VERSION ""

NS_ :

BS_:

BU_: Main_Module Torque_Vector_fpga Driveline a_box OrionBMS torque_vector Dashboard Steering PDU Acceleration bootloader BMS_LV BITSTREAM Charger DAQ a_box ARDUINO TEST_NODE TEST_NODE_2 DAQ

BO_ 2214598913 main_hb: 2 Main_Module
 SG_ precharge_state : 8|1@1+ (1,0) [0|0] "" Vector__XXX
 SG_ car_state : 0|8@1+ (1,0) [0|0] "" Vector__XXX

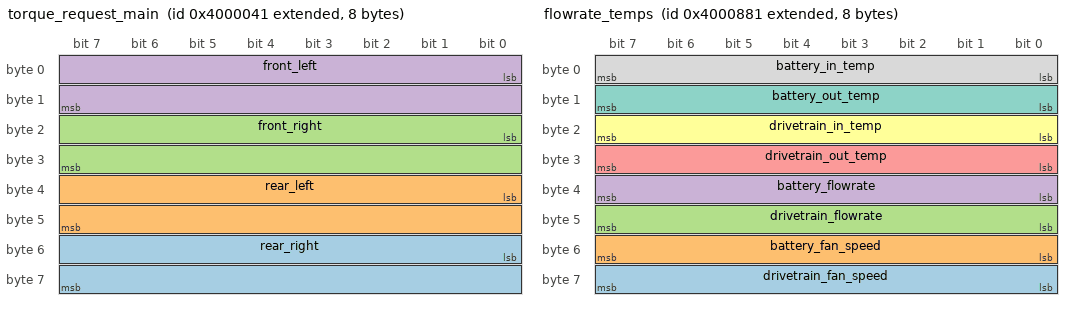
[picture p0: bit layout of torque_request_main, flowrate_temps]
BO_ 2214592577 torque_request_main: 8 Main_Module
 SG_ rear_right : 48|16@1- (1,0) [0|0] "" Vector__XXX
 SG_ rear_left : 32|16@1- (1,0) [0|0] "" Vector__XXX
 SG_ front_right : 16|16@1- (1,0) [0|0] "" Vector__XXX
 SG_ front_left : 0|16@1- (1,0) [0|0] "" Vector__XXX

BO_ 2214594689 flowrate_temps: 8 Main_Module
 SG_ drivetrain_fan_speed : 56|8@1+ (100,0) [0|0] "RPM" Vector__XXX
 SG_ battery_fan_speed : 48|8@1+ (100,0) [0|0] "RPM" Vector__XXX
 SG_ drivetrain_flowrate : 40|8@1+ (0.1,0) [0|0] "LPM" Vector__XXX
 SG_ battery_flowrate : 32|8@1+ (0.1,0) [0|0] "LPM" Vector__XXX
 SG_ drivetrain_out_temp : 24|8@1- (1,0) [0|0] "C" Vector__XXX
 SG_ drivetrain_in_temp : 16|8@1- (1,0) [0|0] "C" Vector__XXX
 SG_ battery_out_temp : 8|8@1- (1,0) [0|0] "C" Vector__XXX
 SG_ battery_in_temp : 0|8@1- (1,0) [0|0] "C" Vector__XXX

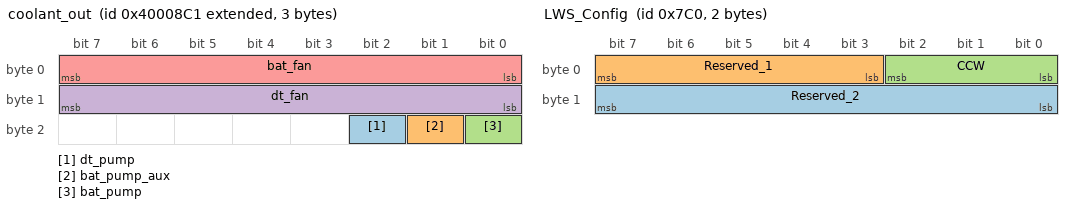
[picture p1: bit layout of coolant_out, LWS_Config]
BO_ 2214594753 coolant_out: 3 Main_Module
 SG_ dt_pump : 18|1@1+ (1,0) [0|0] "" Vector__XXX
 SG_ bat_pump_aux : 17|1@1+ (1,0) [0|0] "" Vector__XXX
 SG_ bat_pump : 16|1@1+ (1,0) [0|0] "" Vector__XXX
 SG_ dt_fan : 8|8@1+ (1,0) [0|0] "%" Vector__XXX
 SG_ bat_fan : 0|8@1+ (1,0) [0|0] "%" Vector__XXX

BO_ 2415921409 gearbox: 2 Main_Module
 SG_ r_temp : 8|8@1- (1,0) [0|0] "" Vector__XXX
 SG_ l_temp : 0|8@1- (1,0) [0|0] "" Vector__XXX

BO_ 1984 LWS_Config: 2 Main_Module
 SG_ Reserved_2 : 8|8@1+ (1,0) [0|0] "" Vector__XXX
 SG_ Reserved_1 : 3|5@1+ (1,0) [0|0] "" Vector__XXX
 SG_ CCW : 0|3@1+ (1,0) [0|0] "" Vector__XXX

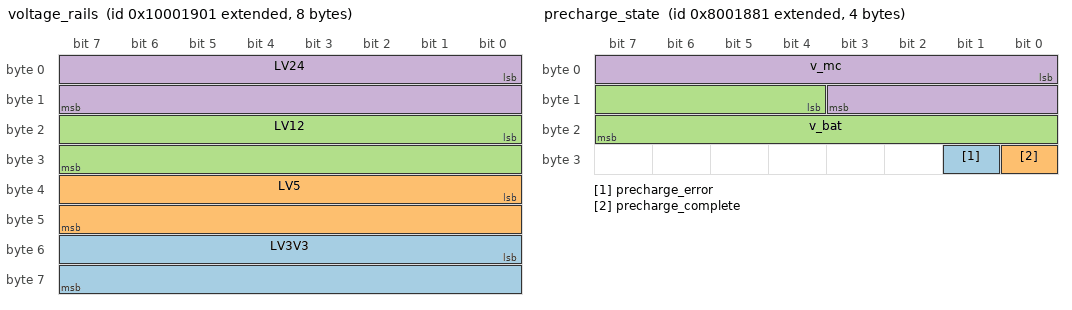
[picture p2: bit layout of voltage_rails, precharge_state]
BO_ 2415925505 voltage_rails: 8 Main_Module
 SG_ LV3V3 : 48|16@1+ (1,0) [0|0] "mV" Vector__XXX
 SG_ LV5 : 32|16@1+ (1,0) [0|0] "mV" Vector__XXX
 SG_ LV12 : 16|16@1+ (1,0) [0|0] "mV" Vector__XXX
 SG_ LV24 : 0|16@1+ (1,0) [0|0] "mV" Vector__XXX

BO_ 2281707649 precharge_state: 4 Main_Module
 SG_ precharge_error : 25|1@1+ (1,0) [0|0] "" Vector__XXX
 SG_ precharge_complete : 24|1@1+ (1,0) [0|0] "" Vector__XXX
 SG_ v_bat : 12|12@1+ (0.1,0) [0|0] "V" Vector__XXX
 SG_ v_mc : 0|12@1+ (0.1,0) [0|0] "V" Vector__XXX

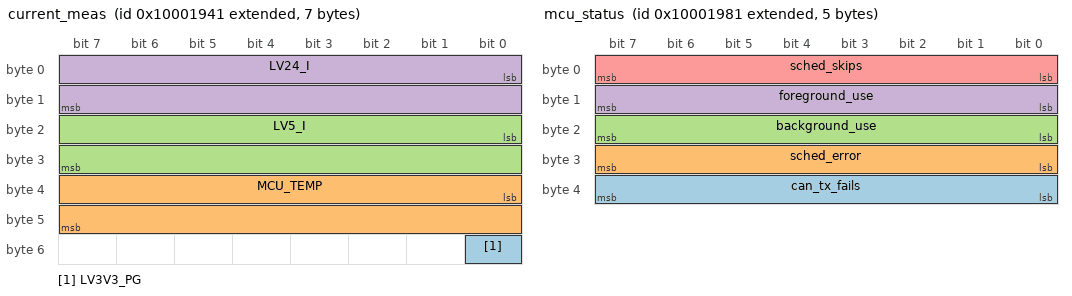
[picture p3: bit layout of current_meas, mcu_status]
BO_ 2415925569 current_meas: 7 Main_Module
 SG_ LV3V3_PG : 48|1@1+ (1,0) [0|0] "" Vector__XXX
 SG_ MCU_TEMP : 32|16@1- (1,0) [0|0] "C" Vector__XXX
 SG_ LV5_I : 16|16@1+ (1,0) [0|0] "mA" Vector__XXX
 SG_ LV24_I : 0|16@1+ (1,0) [0|0] "mA" Vector__XXX

BO_ 2415925633 mcu_status: 5 Main_Module
 SG_ can_tx_fails : 32|8@1+ (1,0) [0|0] "" Vector__XXX
 SG_ sched_error : 24|8@1+ (1,0) [0|0] "" Vector__XXX
 SG_ background_use : 16|8@1+ (1,0) [0|0] "" Vector__XXX
 SG_ foreground_use : 8|8@1+ (1,0) [0|0] "" Vector__XXX
 SG_ sched_skips : 0|8@1+ (1,0) [0|0] "" Vector__XXX

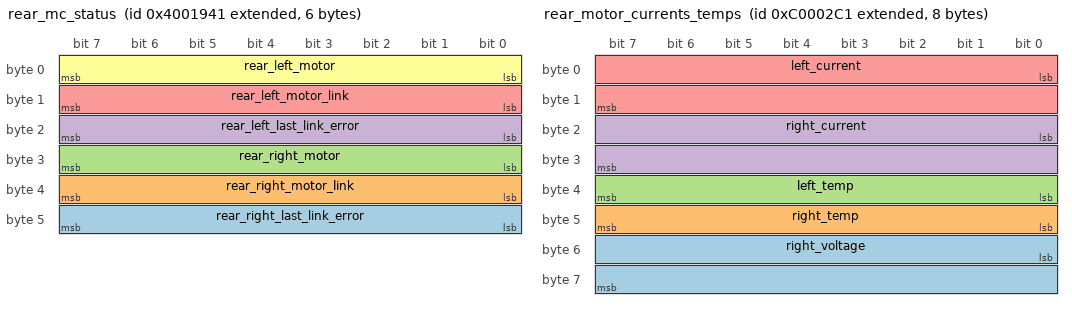
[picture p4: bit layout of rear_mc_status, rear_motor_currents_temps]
BO_ 2214598977 rear_mc_status: 6 Main_Module
 SG_ rear_right_last_link_error : 40|8@1+ (1,0) [0|0] "" Vector__XXX
 SG_ rear_right_motor_link : 32|8@1+ (1,0) [0|0] "" Vector__XXX
 SG_ rear_right_motor : 24|8@1+ (1,0) [0|0] "" Vector__XXX
 SG_ rear_left_last_link_error : 16|8@1+ (1,0) [0|0] "" Vector__XXX
 SG_ rear_left_motor_link : 8|8@1+ (1,0) [0|0] "" Vector__XXX
 SG_ rear_left_motor : 0|8@1+ (1,0) [0|0] "" Vector__XXX

BO_ 2348810945 rear_motor_currents_temps: 8 Main_Module
 SG_ right_voltage : 48|16@1+ (1,0) [0|0] "Voltx10" Vector__XXX
 SG_ right_temp : 40|8@1+ (1,0) [0|0] "C" Vector__XXX
 SG_ left_temp : 32|8@1+ (1,0) [0|0] "C" Vector__XXX
 SG_ right_current : 16|16@1+ (0.1,0) [0|0] "Amp" Vector__XXX
 SG_ left_current : 0|16@1+ (0.1,0) [0|0] "Amp" Vector__XXX

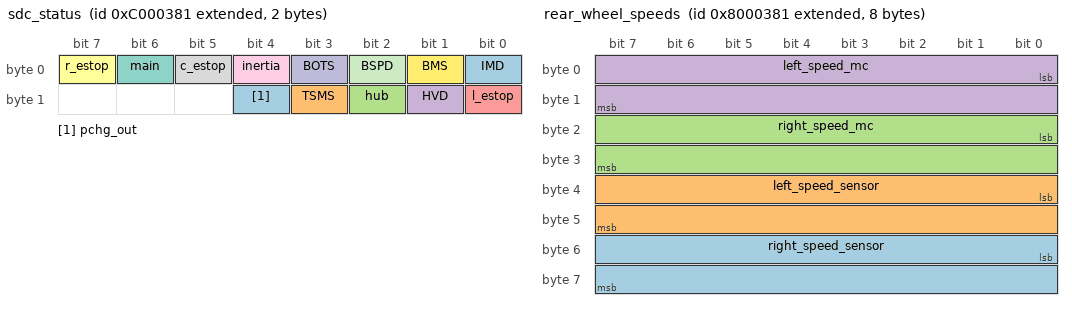
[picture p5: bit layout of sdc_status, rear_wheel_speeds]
BO_ 2348811137 sdc_status: 2 Main_Module
 SG_ pchg_out : 12|1@1+ (1,0) [0|0] "" Vector__XXX
 SG_ TSMS : 11|1@1+ (1,0) [0|0] "" Vector__XXX
 SG_ hub : 10|1@1+ (1,0) [0|0] "" Vector__XXX
 SG_ HVD : 9|1@1+ (1,0) [0|0] "" Vector__XXX
 SG_ l_estop : 8|1@1+ (1,0) [0|0] "" Vector__XXX
 SG_ r_estop : 7|1@1+ (1,0) [0|0] "" Vector__XXX
 SG_ main : 6|1@1+ (1,0) [0|0] "" Vector__XXX
 SG_ c_estop : 5|1@1+ (1,0) [0|0] "" Vector__XXX
 SG_ inertia : 4|1@1+ (1,0) [0|0] "" Vector__XXX
 SG_ BOTS : 3|1@1+ (1,0) [0|0] "" Vector__XXX
 SG_ BSPD : 2|1@1+ (1,0) [0|0] "" Vector__XXX
 SG_ BMS : 1|1@1+ (1,0) [0|0] "" Vector__XXX
 SG_ IMD : 0|1@1+ (1,0) [0|0] "" Vector__XXX

BO_ 2348811009 rear_controller_temps: 2 Main_Module
 SG_ right_temp : 8|8@1+ (1,0) [0|0] "C" Vector__XXX
 SG_ left_temp : 0|8@1+ (1,0) [0|0] "C" Vector__XXX

BO_ 2281702273 rear_wheel_speeds: 8 Main_Module
 SG_ right_speed_sensor : 48|16@1+ (1,0) [0|0] "RPM" Vector__XXX
 SG_ left_speed_sensor : 32|16@1+ (1,0) [0|0] "RPM" Vector__XXX
 SG_ right_speed_mc : 16|16@1+ (1,0) [0|0] "RPM" Vector__XXX
 SG_ left_speed_mc : 0|16@1+ (1,0) [0|0] "RPM" Vector__XXX

BO_ 2148059649 fault_sync_main_module: 3 Main_Module
 SG_ latched : 16|1@1+ (1,0) [0|0] "" Vector__XXX
 SG_ idx : 0|16@1+ (1,0) [0|0] "" Vector__XXX

BO_ 2550136769 daq_response_MAIN_MODULE: 8 Main_Module
 SG_ daq_response : 0|64@1+ (1,0) [0|0] "" Vector__XXX

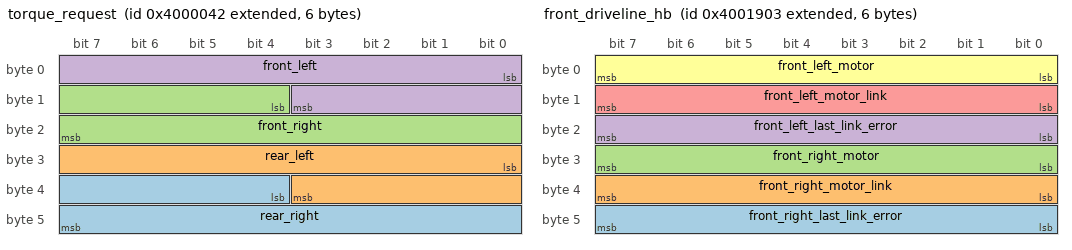
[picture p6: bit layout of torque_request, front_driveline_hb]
BO_ 2214592578 torque_request: 6 Torque_Vector_fpga
 SG_ rear_right : 36|12@1+ (1,0) [0|0] "" Vector__XXX
 SG_ rear_left : 24|12@1+ (1,0) [0|0] "" Vector__XXX
 SG_ front_right : 12|12@1+ (1,0) [0|0] "" Vector__XXX
 SG_ front_left : 0|12@1+ (1,0) [0|0] "" Vector__XXX

BO_ 2147490050 bitstream_flash_status: 1 Torque_Vector_fpga
 SG_ flash_timeout_rx : 1|1@1+ (1,0) [0|0] "" Vector__XXX
 SG_ flash_success : 0|1@1+ (1,0) [0|0] "" Vector__XXX

BO_ 2148059714 fault_sync_torque_vector_fpga: 3 Torque_Vector_fpga
 SG_ latched : 16|1@1+ (1,0) [0|0] "" Vector__XXX
 SG_ idx : 0|16@1+ (1,0) [0|0] "" Vector__XXX

BO_ 2214598915 front_driveline_hb: 6 Driveline
 SG_ front_right_last_link_error : 40|8@1+ (1,0) [0|0] "" Vector__XXX
 SG_ front_right_motor_link : 32|8@1+ (1,0) [0|0] "" Vector__XXX
 SG_ front_right_motor : 24|8@1+ (1,0) [0|0] "" Vector__XXX
 SG_ front_left_last_link_error : 16|8@1+ (1,0) [0|0] "" Vector__XXX
 SG_ front_left_motor_link : 8|8@1+ (1,0) [0|0] "" Vector__XXX
 SG_ front_left_motor : 0|8@1+ (1,0) [0|0] "" Vector__XXX

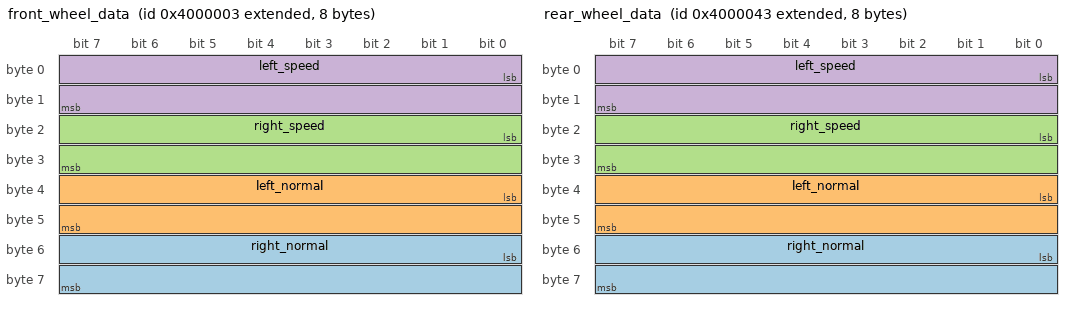
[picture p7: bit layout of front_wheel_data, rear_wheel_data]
BO_ 2214592515 front_wheel_data: 8 Driveline
 SG_ right_normal : 48|16@1+ (0.1,0) [0|0] "mm" Vector__XXX
 SG_ left_normal : 32|16@1+ (0.1,0) [0|0] "mm" Vector__XXX
 SG_ right_speed : 16|16@1+ (1,0) [0|0] "kphx100" Vector__XXX
 SG_ left_speed : 0|16@1+ (1,0) [0|0] "kphx100" Vector__XXX

BO_ 2214592579 rear_wheel_data: 8 Driveline
 SG_ right_normal : 48|16@1+ (0.1,0) [0|0] "mm" Vector__XXX
 SG_ left_normal : 32|16@1+ (0.1,0) [0|0] "mm" Vector__XXX
 SG_ right_speed : 16|16@1+ (1,0) [0|0] "kphx100" Vector__XXX
 SG_ left_speed : 0|16@1+ (1,0) [0|0] "kphx100" Vector__XXX

BO_ 2214593667 rear_mc_req: 8 Driveline
 SG_ right_cmd : 32|32@1- (1,0) [0|0] "%" Vector__XXX
 SG_ left_cmd : 0|32@1- (1,0) [0|0] "%" Vector__XXX

BO_ 2214593731 rear_pow_lim_l: 8 Driveline
 SG_ P_c : 32|32@1- (1,0) [0|0] "W" Vector__XXX
 SG_ T : 0|32@1- (1,0) [0|0] "Nm" Vector__XXX

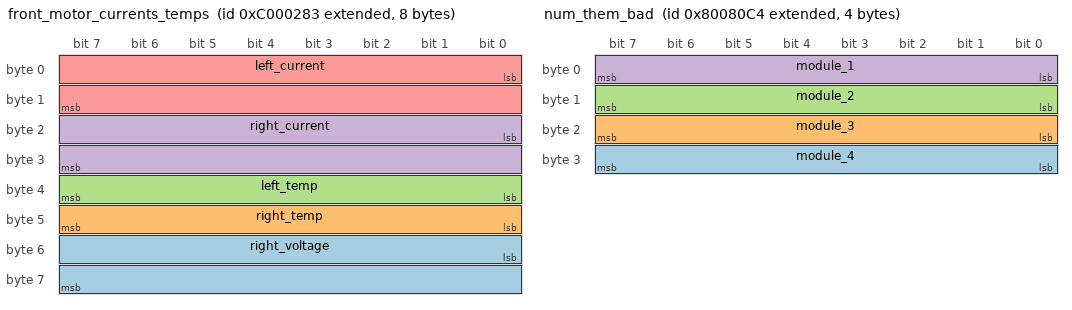
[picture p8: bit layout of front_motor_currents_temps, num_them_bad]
BO_ 2348810883 front_motor_currents_temps: 8 Driveline
 SG_ right_voltage : 48|16@1+ (1,0) [0|0] "Voltx10" Vector__XXX
 SG_ right_temp : 40|8@1+ (1,0) [0|0] "C" Vector__XXX
 SG_ left_temp : 32|8@1+ (1,0) [0|0] "C" Vector__XXX
 SG_ right_current : 16|16@1+ (1,0) [0|0] "Ampx10" Vector__XXX
 SG_ left_current : 0|16@1+ (1,0) [0|0] "Ampx10" Vector__XXX

BO_ 2148059779 fault_sync_driveline: 3 Driveline
 SG_ latched : 16|1@1+ (1,0) [0|0] "" Vector__XXX
 SG_ idx : 0|16@1+ (1,0) [0|0] "" Vector__XXX

BO_ 2550136771 daq_response_DRIVELINE: 8 Driveline
 SG_ daq_response : 0|64@1+ (1,0) [0|0] "" Vector__XXX

BO_ 2214598980 precharge_hb: 2 a_box
 SG_ BMS : 8|8@1+ (1,0) [0|0] "" Vector__XXX
 SG_ IMD : 0|8@1+ (1,0) [0|0] "" Vector__XXX

BO_ 2550588916 elcon_charger_command: 5 a_box
 SG_ charge_disable : 32|1@1+ (1,0) [0|0] "" Vector__XXX
 SG_ current_limit : 16|16@1+ (0.1,0) [0|0] "A" Vector__XXX
 SG_ voltage_limit : 0|16@1+ (0.1,0) [0|0] "V" Vector__XXX

BO_ 2281734340 num_them_bad: 4 a_box
 SG_ module_4 : 24|8@1+ (1,0) [0|0] "" Vector__XXX
 SG_ module_3 : 16|8@1+ (1,0) [0|0] "" Vector__XXX
 SG_ module_2 : 8|8@1+ (1,0) [0|0] "" Vector__XXX
 SG_ module_1 : 0|8@1+ (1,0) [0|0] "" Vector__XXX

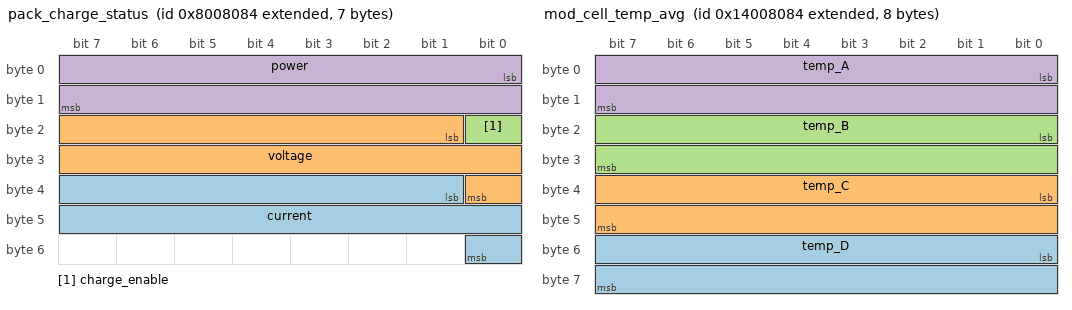
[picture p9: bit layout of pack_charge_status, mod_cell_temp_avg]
BO_ 2281734276 pack_charge_status: 7 a_box
 SG_ current : 33|16@1+ (0.1,0) [0|0] "A" Vector__XXX
 SG_ voltage : 17|16@1+ (0.1,0) [0|0] "V" Vector__XXX
 SG_ charge_enable : 16|1@1+ (1,0) [0|0] "" Vector__XXX
 SG_ power : 0|16@1+ (1,0) [0|0] "W" Vector__XXX

BO_ 2214625284 gyro_data: 6 a_box
 SG_ gz : 32|16@1- (1,0) [0|0] "rad/s*100" Vector__XXX
 SG_ gy : 16|16@1- (1,0) [0|0] "rad/s*100" Vector__XXX
 SG_ gx : 0|16@1- (1,0) [0|0] "rad/s*100" Vector__XXX

BO_ 2214625348 accel_data: 6 a_box
 SG_ az : 32|16@1- (1,0) [0|0] "m/s^2*100" Vector__XXX
 SG_ ay : 16|16@1- (1,0) [0|0] "m/s^2*100" Vector__XXX
 SG_ ax : 0|16@1- (1,0) [0|0] "m/s^2*100" Vector__XXX

BO_ 2214625540 angle_data: 6 a_box
 SG_ yaw : 32|16@1- (1,0) [0|0] "degx10" Vector__XXX
 SG_ roll : 16|16@1- (1,0) [0|0] "degx10" Vector__XXX
 SG_ pitch : 0|16@1- (1,0) [0|0] "degx10" Vector__XXX

BO_ 2214913540 max_cell_temp: 2 a_box
 SG_ max_temp : 0|16@1+ (0.01,0) [0|0] "" Vector__XXX

BO_ 2483060868 mod_cell_temp_avg: 8 a_box
 SG_ temp_D : 48|16@1+ (0.01,0) [0|0] "" Vector__XXX
 SG_ temp_C : 32|16@1+ (0.01,0) [0|0] "" Vector__XXX
 SG_ temp_B : 16|16@1+ (0.01,0) [0|0] "" Vector__XXX
 SG_ temp_A : 0|16@1+ (0.01,0) [0|0] "" Vector__XXX

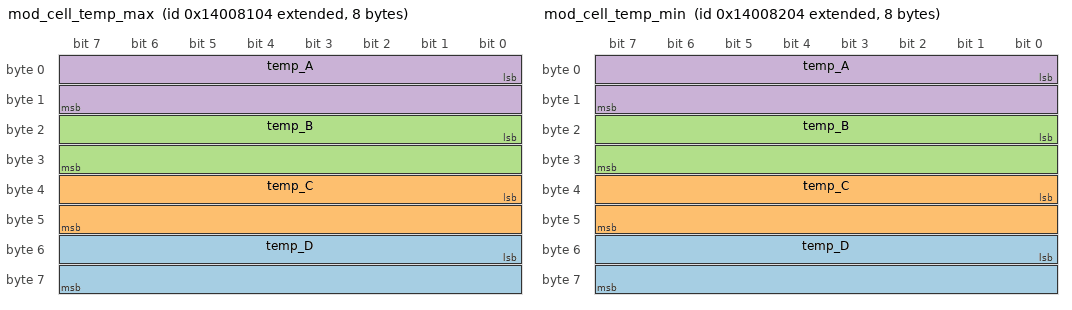
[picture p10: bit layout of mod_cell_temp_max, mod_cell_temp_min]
BO_ 2483060996 mod_cell_temp_max: 8 a_box
 SG_ temp_D : 48|16@1+ (0.01,0) [0|0] "" Vector__XXX
 SG_ temp_C : 32|16@1+ (0.01,0) [0|0] "" Vector__XXX
 SG_ temp_B : 16|16@1+ (0.01,0) [0|0] "" Vector__XXX
 SG_ temp_A : 0|16@1+ (0.01,0) [0|0] "" Vector__XXX

BO_ 2483061252 mod_cell_temp_min: 8 a_box
 SG_ temp_D : 48|16@1+ (0.01,0) [0|0] "" Vector__XXX
 SG_ temp_C : 32|16@1+ (0.01,0) [0|0] "" Vector__XXX
 SG_ temp_B : 16|16@1+ (0.01,0) [0|0] "" Vector__XXX
 SG_ temp_A : 0|16@1+ (0.01,0) [0|0] "" Vector__XXX

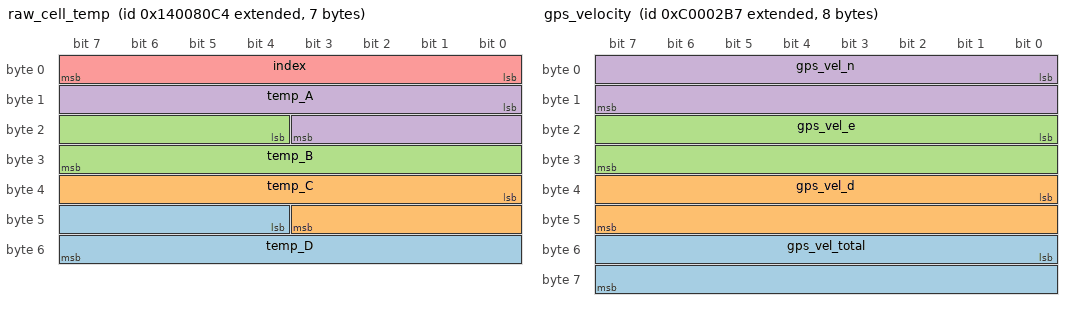
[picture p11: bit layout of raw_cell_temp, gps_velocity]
BO_ 2483060932 raw_cell_temp: 7 a_box
 SG_ temp_D : 44|12@1+ (0.01,0) [0|0] "C" Vector__XXX
 SG_ temp_C : 32|12@1+ (0.01,0) [0|0] "C" Vector__XXX
 SG_ temp_B : 20|12@1+ (0.01,0) [0|0] "C" Vector__XXX
 SG_ temp_A : 8|12@1+ (0.01,0) [0|0] "C" Vector__XXX
 SG_ index : 0|8@1+ (1,0) [0|0] "" Vector__XXX

BO_ 2148059844 fault_sync_a_box: 3 a_box
 SG_ latched : 16|1@1+ (1,0) [0|0] "" Vector__XXX
 SG_ idx : 0|16@1+ (1,0) [0|0] "" Vector__XXX

BO_ 2550136772 daq_response_A_BOX: 8 a_box
 SG_ daq_response : 0|64@1+ (1,0) [0|0] "" Vector__XXX

BO_ 2483029688 orion_info: 7 OrionBMS
 SG_ pack_soc : 48|8@1+ (0.5,0) [0|0] "%" Vector__XXX
 SG_ pack_ccl : 32|16@1+ (1,0) [0|0] "A" Vector__XXX
 SG_ pack_dcl : 16|16@1+ (1,0) [0|0] "A" Vector__XXX
 SG_ multi_output_1 : 15|1@1+ (1,0) [0|0] "" Vector__XXX
 SG_ multi_enable : 14|1@1+ (1,0) [0|0] "" Vector__XXX
 SG_ multi_output_4 : 13|1@1+ (1,0) [0|0] "" Vector__XXX
 SG_ multi_output_3 : 12|1@1+ (1,0) [0|0] "" Vector__XXX
 SG_ multi_output_2 : 11|1@1+ (1,0) [0|0] "" Vector__XXX
 SG_ reserved : 10|1@1+ (1,0) [0|0] "" Vector__XXX
 SG_ multi_input_3 : 9|1@1+ (1,0) [0|0] "" Vector__XXX
 SG_ multi_input_2 : 8|1@1+ (1,0) [0|0] "" Vector__XXX
 SG_ is_charging : 7|1@1+ (1,0) [0|0] "" Vector__XXX
 SG_ is_ready : 6|1@1+ (1,0) [0|0] "" Vector__XXX
 SG_ always_on : 5|1@1+ (1,0) [0|0] "" Vector__XXX
 SG_ multi_input : 4|1@1+ (1,0) [0|0] "" Vector__XXX
 SG_ dtc_status : 3|1@1+ (1,0) [0|0] "" Vector__XXX
 SG_ charger_safety : 2|1@1+ (1,0) [0|0] "" Vector__XXX
 SG_ charge_enable : 1|1@1+ (1,0) [0|0] "" Vector__XXX
 SG_ discharge_enable : 0|1@1+ (1,0) [0|0] "" Vector__XXX

BO_ 2483029752 orion_currents_volts: 4 OrionBMS
 SG_ pack_voltage : 16|16@1+ (0.1,0) [0|0] "V" Vector__XXX
 SG_ pack_current : 0|16@1- (0.1,0) [0|0] "A" Vector__XXX

BO_ 2348812088 orion_errors: 4 OrionBMS
 SG_ charge_limit_enforce : 31|1@1+ (1,0) [0|0] "" Vector__XXX
 SG_ input_psu : 30|1@1+ (1,0) [0|0] "" Vector__XXX
 SG_ hv_isolation : 29|1@1+ (1,0) [0|0] "" Vector__XXX
 SG_ redundant_psu : 28|1@1+ (1,0) [0|0] "" Vector__XXX
 SG_ external_comms : 27|1@1+ (1,0) [0|0] "" Vector__XXX
 SG_ thermistor : 26|1@1+ (1,0) [0|0] "" Vector__XXX
 SG_ fan_monitor : 25|1@1+ (1,0) [0|0] "" Vector__XXX
 SG_ weak_pack : 24|1@1+ (1,0) [0|0] "" Vector__XXX
 SG_ cell_asic : 23|1@1+ (1,0) [0|0] "" Vector__XXX
 SG_ max_cellv_o5v : 22|1@1+ (1,0) [0|0] "" Vector__XXX
 SG_ current_sensor : 21|1@1+ (1,0) [0|0] "" Vector__XXX
 SG_ open_wire : 20|1@1+ (1,0) [0|0] "" Vector__XXX
 SG_ low_cellv : 19|1@1+ (1,0) [0|0] "" Vector__XXX
 SG_ weak_cell : 18|1@1+ (1,0) [0|0] "" Vector__XXX
 SG_ cell_balancing_foff : 17|1@1+ (1,0) [0|0] "" Vector__XXX
 SG_ internal_comms : 16|1@1+ (1,0) [0|0] "" Vector__XXX
 SG_ reserved7 : 15|1@1+ (1,0) [0|0] "" Vector__XXX
 SG_ reserved6 : 14|1@1+ (1,0) [0|0] "" Vector__XXX
 SG_ reserved5 : 13|1@1+ (1,0) [0|0] "" Vector__XXX
 SG_ reserved4 : 12|1@1+ (1,0) [0|0] "" Vector__XXX
 SG_ reserved3 : 11|1@1+ (1,0) [0|0] "" Vector__XXX
 SG_ reserved2 : 10|1@1+ (1,0) [0|0] "" Vector__XXX
 SG_ reserved1 : 9|1@1+ (1,0) [0|0] "" Vector__XXX
 SG_ reserved0 : 8|1@1+ (1,0) [0|0] "" Vector__XXX
 SG_ pack_overheat : 7|1@1+ (1,0) [0|0] "" Vector__XXX
 SG_ min_cellv_low : 6|1@1+ (1,0) [0|0] "" Vector__XXX
 SG_ max_cellv_high : 5|1@1+ (1,0) [0|0] "" Vector__XXX
 SG_ software : 4|1@1+ (1,0) [0|0] "" Vector__XXX
 SG_ heatsink_thermistor : 3|1@1+ (1,0) [0|0] "" Vector__XXX
 SG_ internal_hardware : 2|1@1+ (1,0) [0|0] "" Vector__XXX
 SG_ charger_safety_relay : 1|1@1+ (1,0) [0|0] "" Vector__XXX
 SG_ discharge_limit_enforce : 0|1@1+ (1,0) [0|0] "" Vector__XXX

BO_ 2348810935 gps_velocity: 8 torque_vector
 SG_ gps_vel_total : 48|16@1- (0.01,0) [0|0] "m/s" Vector__XXX
 SG_ gps_vel_d : 32|16@1- (0.01,0) [0|0] "m/s" Vector__XXX
 SG_ gps_vel_e : 16|16@1- (0.01,0) [0|0] "m/s" Vector__XXX
 SG_ gps_vel_n : 0|16@1- (0.01,0) [0|0] "m/s" Vector__XXX

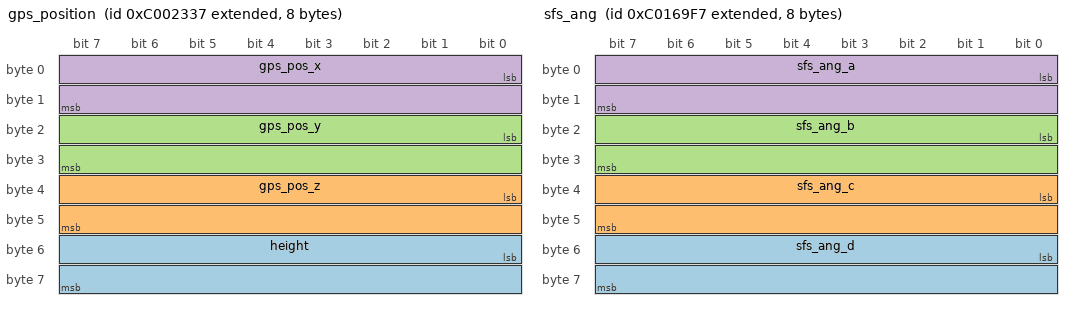
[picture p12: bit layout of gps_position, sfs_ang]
BO_ 2348819255 gps_position: 8 torque_vector
 SG_ height : 48|16@1- (0.01,0) [0|0] "m" Vector__XXX
 SG_ gps_pos_z : 32|16@1- (0.01,0) [0|0] "m" Vector__XXX
 SG_ gps_pos_y : 16|16@1- (0.01,0) [0|0] "m" Vector__XXX
 SG_ gps_pos_x : 0|16@1- (0.01,0) [0|0] "m" Vector__XXX

BO_ 2348819319 gps_coordinates: 8 torque_vector
 SG_ longitude : 32|32@1- (1,0) [0|0] "deg" Vector__XXX
 SG_ latitude : 0|32@1- (1,0) [0|0] "deg" Vector__XXX

BO_ 2348810999 imu_gyro: 6 torque_vector
 SG_ imu_gyro_z : 32|16@1- (0.01,0) [0|0] "rad/s" Vector__XXX
 SG_ imu_gyro_y : 16|16@1- (0.01,0) [0|0] "rad/s" Vector__XXX
 SG_ imu_gyro_x : 0|16@1- (0.01,0) [0|0] "rad/s" Vector__XXX

BO_ 2348819383 imu_accel: 6 torque_vector
 SG_ imu_accel_z : 32|16@1- (0.01,0) [0|0] "m/s^2" Vector__XXX
 SG_ imu_accel_y : 16|16@1- (0.01,0) [0|0] "m/s^2" Vector__XXX
 SG_ imu_accel_x : 0|16@1- (0.01,0) [0|0] "m/s^2" Vector__XXX

BO_ 2348819447 bmm_mag: 6 torque_vector
 SG_ bmm_mag_z : 32|16@1- (1,0) [0|0] "uT" Vector__XXX
 SG_ bmm_mag_y : 16|16@1- (1,0) [0|0] "uT" Vector__XXX
 SG_ bmm_mag_x : 0|16@1- (1,0) [0|0] "uT" Vector__XXX

BO_ 2348902711 sfs_pos: 6 torque_vector
 SG_ sfs_pos_z : 32|16@1- (0.01,0) [0|0] "m" Vector__XXX
 SG_ sfs_pos_y : 16|16@1- (0.01,0) [0|0] "m" Vector__XXX
 SG_ sfs_pos_x : 0|16@1- (0.01,0) [0|0] "m" Vector__XXX

BO_ 2348902775 sfs_vel: 6 torque_vector
 SG_ sfs_vel_z : 32|16@1- (0.01,0) [0|0] "m/s" Vector__XXX
 SG_ sfs_vel_y : 16|16@1- (0.01,0) [0|0] "m/s" Vector__XXX
 SG_ sfs_vel_x : 0|16@1- (0.01,0) [0|0] "m/s" Vector__XXX

BO_ 2348902839 sfs_acc: 6 torque_vector
 SG_ sfs_acc_z : 32|16@1- (0.01,0) [0|0] "m/s^2" Vector__XXX
 SG_ sfs_acc_y : 16|16@1- (0.01,0) [0|0] "m/s^2" Vector__XXX
 SG_ sfs_acc_x : 0|16@1- (0.01,0) [0|0] "m/s^2" Vector__XXX

BO_ 2348902903 sfs_ang: 8 torque_vector
 SG_ sfs_ang_d : 48|16@1- (0.0001,0) [0|0] "" Vector__XXX
 SG_ sfs_ang_c : 32|16@1- (0.0001,0) [0|0] "" Vector__XXX
 SG_ sfs_ang_b : 16|16@1- (0.0001,0) [0|0] "" Vector__XXX
 SG_ sfs_ang_a : 0|16@1- (0.0001,0) [0|0] "" Vector__XXX

BO_ 2348902967 sfs_ang_vel: 6 torque_vector
 SG_ sfs_ang_vel_z : 32|16@1- (0.0001,0) [0|0] "" Vector__XXX
 SG_ sfs_ang_vel_y : 16|16@1- (0.0001,0) [0|0] "" Vector__XXX
 SG_ sfs_ang_vel_x : 0|16@1- (0.0001,0) [0|0] "" Vector__XXX

BO_ 2348819895 throttle_remapped: 4 torque_vector
 SG_ remap_k_rr : 16|16@1- (1,0) [0|0] "none" Vector__XXX
 SG_ remap_k_rl : 0|16@1- (1,0) [0|0] "none" Vector__XXX

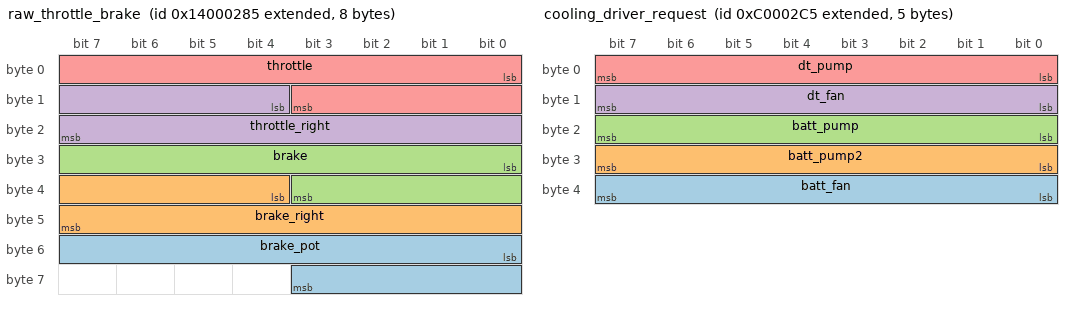
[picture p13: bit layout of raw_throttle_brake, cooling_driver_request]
BO_ 2483028613 raw_throttle_brake: 8 Dashboard
 SG_ brake_pot : 48|12@1+ (0.02442,0) [0|0] "%" Vector__XXX
 SG_ brake_right : 36|12@1+ (0.02442,0) [0|0] "%" Vector__XXX
 SG_ brake : 24|12@1+ (0.02442,0) [0|0] "%" Vector__XXX
 SG_ throttle_right : 12|12@1+ (0.02442,0) [0|0] "%" Vector__XXX
 SG_ throttle : 0|12@1+ (0.02442,0) [0|0] "%" Vector__XXX

BO_ 2348810949 cooling_driver_request: 5 Dashboard
 SG_ batt_fan : 32|8@1+ (1,0) [0|0] "" Vector__XXX
 SG_ batt_pump2 : 24|8@1+ (1,0) [0|0] "" Vector__XXX
 SG_ batt_pump : 16|8@1+ (1,0) [0|0] "" Vector__XXX
 SG_ dt_fan : 8|8@1+ (1,0) [0|0] "" Vector__XXX
 SG_ dt_pump : 0|8@1+ (1,0) [0|0] "" Vector__XXX

BO_ 2214593093 filt_throttle_brake: 3 Dashboard
 SG_ brake : 12|12@1+ (0.02442,0) [0|0] "%" Vector__XXX
 SG_ throttle : 0|12@1+ (0.02442,0) [0|0] "%" Vector__XXX

BO_ 2214592517 start_button: 1 Dashboard
 SG_ start : 0|1@1+ (1,0) [0|0] "" Vector__XXX

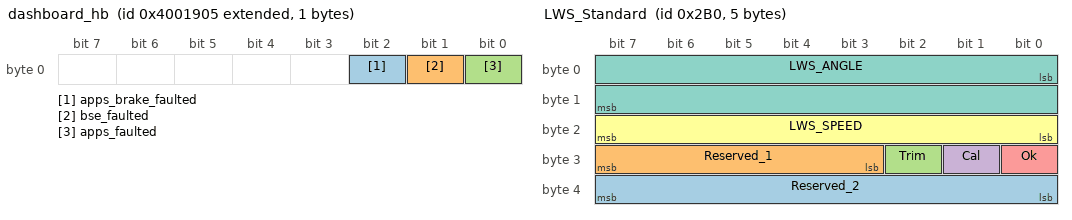
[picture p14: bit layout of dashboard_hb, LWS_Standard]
BO_ 2214598917 dashboard_hb: 1 Dashboard
 SG_ apps_brake_faulted : 2|1@1+ (1,0) [0|0] "" Vector__XXX
 SG_ bse_faulted : 1|1@1+ (1,0) [0|0] "" Vector__XXX
 SG_ apps_faulted : 0|1@1+ (1,0) [0|0] "" Vector__XXX

BO_ 2214598981 dashboard_volts_temp: 6 Dashboard
 SG_ volts_3v3 : 32|16@1+ (1,0) [0|0] "" Vector__XXX
 SG_ volts_5v : 16|16@1+ (1,0) [0|0] "" Vector__XXX
 SG_ mcu_temp : 0|16@1- (1,0) [0|0] "" Vector__XXX

BO_ 2148059909 fault_sync_dashboard: 3 Dashboard
 SG_ latched : 16|1@1+ (1,0) [0|0] "" Vector__XXX
 SG_ idx : 0|16@1+ (1,0) [0|0] "" Vector__XXX

BO_ 2550136773 daq_response_DASHBOARD: 8 Dashboard
 SG_ daq_response : 0|64@1+ (1,0) [0|0] "" Vector__XXX

BO_ 688 LWS_Standard: 5 Steering
 SG_ Reserved_2 : 32|8@1+ (1,0) [0|0] "" Vector__XXX
 SG_ Reserved_1 : 27|5@1+ (1,0) [0|0] "" Vector__XXX
 SG_ Trim : 26|1@1+ (1,0) [0|0] "" Vector__XXX
 SG_ Cal : 25|1@1+ (1,0) [0|0] "" Vector__XXX
 SG_ Ok : 24|1@1+ (1,0) [0|0] "" Vector__XXX
 SG_ LWS_SPEED : 16|8@1+ (4,0) [0|0] "deg/s" Vector__XXX
 SG_ LWS_ANGLE : 0|16@1- (0.1,0) [0|0] "deg" Vector__XXX

BO_ 2214659103 pdu_test: 3 PDU
 SG_ test_3 : 16|8@1+ (1,0) [0|0] "" Vector__XXX
 SG_ test_2 : 8|8@1+ (1,0) [0|0] "" Vector__XXX
 SG_ test_1 : 0|8@1+ (1,0) [0|0] "" Vector__XXX

BO_ 2148059999 fault_sync_pdu: 3 PDU
 SG_ latched : 16|1@1+ (1,0) [0|0] "" Vector__XXX
 SG_ idx : 0|16@1+ (1,0) [0|0] "" Vector__XXX

BO_ 2550136799 daq_response_PDU: 8 PDU
 SG_ daq_response : 0|64@1+ (1,0) [0|0] "" Vector__XXX

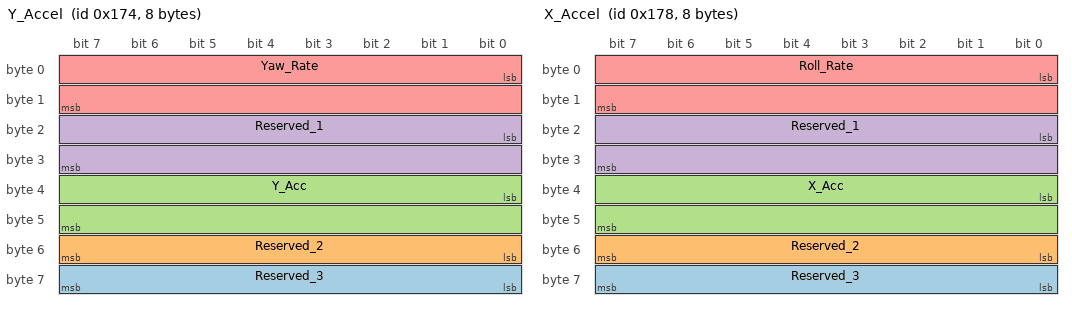
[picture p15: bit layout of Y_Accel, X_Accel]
BO_ 372 Y_Accel: 8 Acceleration
 SG_ Reserved_3 : 56|8@1+ (1,0) [0|0] "" Vector__XXX
 SG_ Reserved_2 : 48|8@1+ (1,0) [0|0] "" Vector__XXX
 SG_ Y_Acc : 32|16@1+ (0.0001274,-4.1746432) [0|0] "g" Vector__XXX
 SG_ Reserved_1 : 16|16@1+ (1,0) [0|0] "" Vector__XXX
 SG_ Yaw_Rate : 0|16@1+ (0.005,-163.84) [0|0] "°/s" Vector__XXX

BO_ 376 X_Accel: 8 Acceleration
 SG_ Reserved_3 : 56|8@1+ (1,0) [0|0] "" Vector__XXX
 SG_ Reserved_2 : 48|8@1+ (1,0) [0|0] "" Vector__XXX
 SG_ X_Acc : 32|16@1+ (0.0001274,-4.1746432) [0|0] "g" Vector__XXX
 SG_ Reserved_1 : 16|16@1+ (1,0) [0|0] "" Vector__XXX
 SG_ Roll_Rate : 0|16@1+ (0.005,-163.84) [0|0] "°/s" Vector__XXX

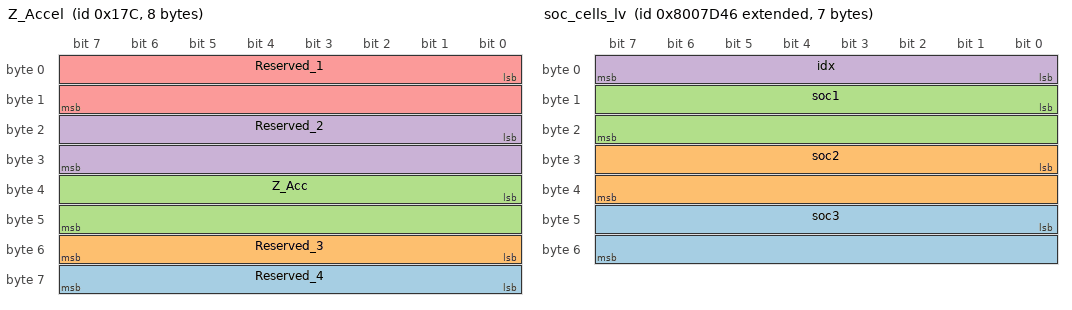
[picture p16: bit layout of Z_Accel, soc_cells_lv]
BO_ 380 Z_Accel: 8 Acceleration
 SG_ Reserved_4 : 56|8@1+ (1,0) [0|0] "" Vector__XXX
 SG_ Reserved_3 : 48|8@1+ (1,0) [0|0] "" Vector__XXX
 SG_ Z_Acc : 32|16@1+ (0.0001274,-4.1746432) [0|0] "g" Vector__XXX
 SG_ Reserved_2 : 16|16@1+ (1,0) [0|0] "" Vector__XXX
 SG_ Reserved_1 : 0|16@1+ (1,0) [0|0] "" Vector__XXX

BO_ 2214912572 main_module_bl_resp: 5 bootloader
 SG_ data : 8|32@1+ (1,0) [0|0] "" Vector__XXX
 SG_ cmd : 0|8@1+ (1,0) [0|0] "" Vector__XXX

BO_ 2214912636 dashboard_bl_resp: 5 bootloader
 SG_ data : 8|32@1+ (1,0) [0|0] "" Vector__XXX
 SG_ cmd : 0|8@1+ (1,0) [0|0] "" Vector__XXX

BO_ 2214912700 torquevector_bl_resp: 5 bootloader
 SG_ data : 8|32@1+ (1,0) [0|0] "" Vector__XXX
 SG_ cmd : 0|8@1+ (1,0) [0|0] "" Vector__XXX

BO_ 2214912764 driveline_front_bl_resp: 5 bootloader
 SG_ data : 8|32@1+ (1,0) [0|0] "" Vector__XXX
 SG_ cmd : 0|8@1+ (1,0) [0|0] "" Vector__XXX

BO_ 2214912828 driveline_rear_bl_resp: 5 bootloader
 SG_ data : 8|32@1+ (1,0) [0|0] "" Vector__XXX
 SG_ cmd : 0|8@1+ (1,0) [0|0] "" Vector__XXX

BO_ 2214912892 precharge_bl_resp: 5 bootloader
 SG_ data : 8|32@1+ (1,0) [0|0] "" Vector__XXX
 SG_ cmd : 0|8@1+ (1,0) [0|0] "" Vector__XXX

BO_ 2214912956 bms_a_bl_resp: 5 bootloader
 SG_ data : 8|32@1+ (1,0) [0|0] "" Vector__XXX
 SG_ cmd : 0|8@1+ (1,0) [0|0] "" Vector__XXX

BO_ 2214913020 bms_b_bl_resp: 5 bootloader
 SG_ data : 8|32@1+ (1,0) [0|0] "" Vector__XXX
 SG_ cmd : 0|8@1+ (1,0) [0|0] "" Vector__XXX

BO_ 2214913084 bms_c_bl_resp: 5 bootloader
 SG_ data : 8|32@1+ (1,0) [0|0] "" Vector__XXX
 SG_ cmd : 0|8@1+ (1,0) [0|0] "" Vector__XXX

BO_ 2214913148 bms_d_bl_resp: 5 bootloader
 SG_ data : 8|32@1+ (1,0) [0|0] "" Vector__XXX
 SG_ cmd : 0|8@1+ (1,0) [0|0] "" Vector__XXX

BO_ 2214913212 bms_e_bl_resp: 5 bootloader
 SG_ data : 8|32@1+ (1,0) [0|0] "" Vector__XXX
 SG_ cmd : 0|8@1+ (1,0) [0|0] "" Vector__XXX

BO_ 2214913276 bms_f_bl_resp: 5 bootloader
 SG_ data : 8|32@1+ (1,0) [0|0] "" Vector__XXX
 SG_ cmd : 0|8@1+ (1,0) [0|0] "" Vector__XXX

BO_ 2214913340 bms_g_bl_resp: 5 bootloader
 SG_ data : 8|32@1+ (1,0) [0|0] "" Vector__XXX
 SG_ cmd : 0|8@1+ (1,0) [0|0] "" Vector__XXX

BO_ 2214913404 bms_h_bl_resp: 5 bootloader
 SG_ data : 8|32@1+ (1,0) [0|0] "" Vector__XXX
 SG_ cmd : 0|8@1+ (1,0) [0|0] "" Vector__XXX

BO_ 2214913468 bms_i_bl_resp: 5 bootloader
 SG_ data : 8|32@1+ (1,0) [0|0] "" Vector__XXX
 SG_ cmd : 0|8@1+ (1,0) [0|0] "" Vector__XXX

BO_ 2214913532 bms_j_bl_resp: 5 bootloader
 SG_ data : 8|32@1+ (1,0) [0|0] "" Vector__XXX
 SG_ cmd : 0|8@1+ (1,0) [0|0] "" Vector__XXX

BO_ 2214913596 l4_testing_bl_resp: 5 bootloader
 SG_ data : 8|32@1+ (1,0) [0|0] "" Vector__XXX
 SG_ cmd : 0|8@1+ (1,0) [0|0] "" Vector__XXX

BO_ 2281733446 soc_cells_lv: 7 BMS_LV
 SG_ soc3 : 40|16@1+ (1,0) [0|0] "" Vector__XXX
 SG_ soc2 : 24|16@1+ (1,0) [0|0] "" Vector__XXX
 SG_ soc1 : 8|16@1+ (1,0) [0|0] "" Vector__XXX
 SG_ idx : 0|8@1+ (1,0) [0|0] "" Vector__XXX

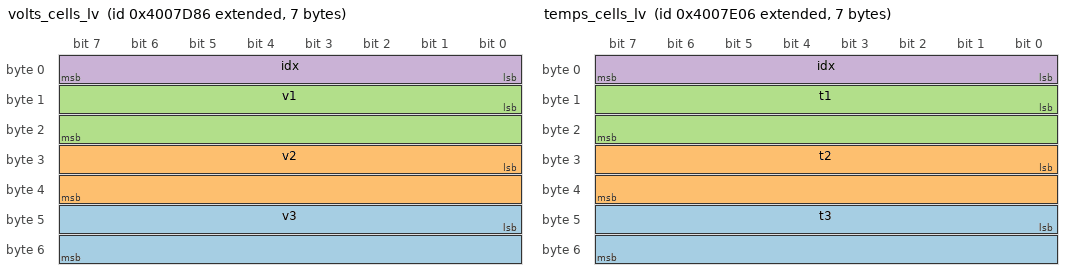
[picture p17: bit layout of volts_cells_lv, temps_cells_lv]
BO_ 2214624646 volts_cells_lv: 7 BMS_LV
 SG_ v3 : 40|16@1+ (1,0) [0|0] "" Vector__XXX
 SG_ v2 : 24|16@1+ (1,0) [0|0] "" Vector__XXX
 SG_ v1 : 8|16@1+ (1,0) [0|0] "" Vector__XXX
 SG_ idx : 0|8@1+ (1,0) [0|0] "" Vector__XXX

BO_ 2281733574 pack_info_lv: 6 BMS_LV
 SG_ bal_flags : 32|16@1+ (1,0) [0|0] "" Vector__XXX
 SG_ error : 16|16@1+ (1,0) [0|0] "" Vector__XXX
 SG_ volts : 0|16@1+ (1,0) [0|0] "" Vector__XXX

BO_ 2214624774 temps_cells_lv: 7 BMS_LV
 SG_ t3 : 40|16@1+ (1,0) [0|0] "" Vector__XXX
 SG_ t2 : 24|16@1+ (1,0) [0|0] "" Vector__XXX
 SG_ t1 : 8|16@1+ (1,0) [0|0] "" Vector__XXX
 SG_ idx : 0|8@1+ (1,0) [0|0] "" Vector__XXX

BO_ 2281733702 cell_info_lv: 6 BMS_LV
 SG_ uv : 32|16@1+ (1,0) [0|0] "" Vector__XXX
 SG_ ov : 16|16@1+ (1,0) [0|0] "" Vector__XXX
 SG_ delta : 0|16@1+ (1,0) [0|0] "" Vector__XXX

BO_ 2214624902 power_lim_lv: 4 BMS_LV
 SG_ chg_lim : 16|16@1+ (1,0) [0|0] "" Vector__XXX
 SG_ disch_lim : 0|16@1+ (1,0) [0|0] "" Vector__XXX

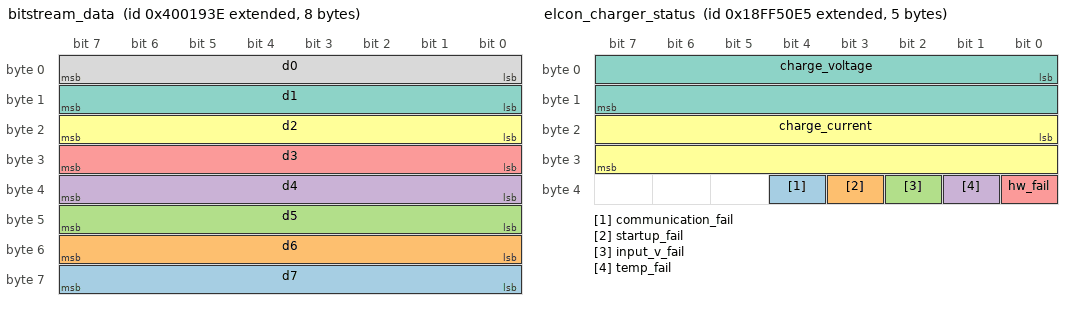
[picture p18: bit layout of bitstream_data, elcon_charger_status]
BO_ 2214598974 bitstream_data: 8 BITSTREAM
 SG_ d7 : 56|8@1+ (1,0) [0|0] "" Vector__XXX
 SG_ d6 : 48|8@1+ (1,0) [0|0] "" Vector__XXX
 SG_ d5 : 40|8@1+ (1,0) [0|0] "" Vector__XXX
 SG_ d4 : 32|8@1+ (1,0) [0|0] "" Vector__XXX
 SG_ d3 : 24|8@1+ (1,0) [0|0] "" Vector__XXX
 SG_ d2 : 16|8@1+ (1,0) [0|0] "" Vector__XXX
 SG_ d1 : 8|8@1+ (1,0) [0|0] "" Vector__XXX
 SG_ d0 : 0|8@1+ (1,0) [0|0] "" Vector__XXX

BO_ 2415925630 bitstream_request: 5 BITSTREAM
 SG_ download_size : 1|32@1+ (1,0) [0|0] "" Vector__XXX
 SG_ download_request : 0|1@1+ (1,0) [0|0] "" Vector__XXX

BO_ 2215232574 main_module_bl_cmd: 5 BITSTREAM
 SG_ data : 8|32@1+ (1,0) [0|0] "" Vector__XXX
 SG_ cmd : 0|8@1+ (1,0) [0|0] "" Vector__XXX

BO_ 2215232638 dashboard_bl_cmd: 5 BITSTREAM
 SG_ data : 8|32@1+ (1,0) [0|0] "" Vector__XXX
 SG_ cmd : 0|8@1+ (1,0) [0|0] "" Vector__XXX

BO_ 2215232702 torquevector_bl_cmd: 5 BITSTREAM
 SG_ data : 8|32@1+ (1,0) [0|0] "" Vector__XXX
 SG_ cmd : 0|8@1+ (1,0) [0|0] "" Vector__XXX

BO_ 2215232766 driveline_front_bl_cmd: 5 BITSTREAM
 SG_ data : 8|32@1+ (1,0) [0|0] "" Vector__XXX
 SG_ cmd : 0|8@1+ (1,0) [0|0] "" Vector__XXX

BO_ 2215232830 driveline_rear_bl_cmd: 5 BITSTREAM
 SG_ data : 8|32@1+ (1,0) [0|0] "" Vector__XXX
 SG_ cmd : 0|8@1+ (1,0) [0|0] "" Vector__XXX

BO_ 2215232894 precharge_bl_cmd: 5 BITSTREAM
 SG_ data : 8|32@1+ (1,0) [0|0] "" Vector__XXX
 SG_ cmd : 0|8@1+ (1,0) [0|0] "" Vector__XXX

BO_ 2215232958 bms_a_bl_cmd: 5 BITSTREAM
 SG_ data : 8|32@1+ (1,0) [0|0] "" Vector__XXX
 SG_ cmd : 0|8@1+ (1,0) [0|0] "" Vector__XXX

BO_ 2215233022 bms_b_bl_cmd: 5 BITSTREAM
 SG_ data : 8|32@1+ (1,0) [0|0] "" Vector__XXX
 SG_ cmd : 0|8@1+ (1,0) [0|0] "" Vector__XXX

BO_ 2215233086 bms_c_bl_cmd: 5 BITSTREAM
 SG_ data : 8|32@1+ (1,0) [0|0] "" Vector__XXX
 SG_ cmd : 0|8@1+ (1,0) [0|0] "" Vector__XXX

BO_ 2215233150 bms_d_bl_cmd: 5 BITSTREAM
 SG_ data : 8|32@1+ (1,0) [0|0] "" Vector__XXX
 SG_ cmd : 0|8@1+ (1,0) [0|0] "" Vector__XXX

BO_ 2215233214 bms_e_bl_cmd: 5 BITSTREAM
 SG_ data : 8|32@1+ (1,0) [0|0] "" Vector__XXX
 SG_ cmd : 0|8@1+ (1,0) [0|0] "" Vector__XXX

BO_ 2215233278 bms_f_bl_cmd: 5 BITSTREAM
 SG_ data : 8|32@1+ (1,0) [0|0] "" Vector__XXX
 SG_ cmd : 0|8@1+ (1,0) [0|0] "" Vector__XXX

BO_ 2215233342 bms_g_bl_cmd: 5 BITSTREAM
 SG_ data : 8|32@1+ (1,0) [0|0] "" Vector__XXX
 SG_ cmd : 0|8@1+ (1,0) [0|0] "" Vector__XXX

BO_ 2215233406 bms_h_bl_cmd: 5 BITSTREAM
 SG_ data : 8|32@1+ (1,0) [0|0] "" Vector__XXX
 SG_ cmd : 0|8@1+ (1,0) [0|0] "" Vector__XXX

BO_ 2215233470 bms_i_bl_cmd: 5 BITSTREAM
 SG_ data : 8|32@1+ (1,0) [0|0] "" Vector__XXX
 SG_ cmd : 0|8@1+ (1,0) [0|0] "" Vector__XXX

BO_ 2215233534 bms_j_bl_cmd: 5 BITSTREAM
 SG_ data : 8|32@1+ (1,0) [0|0] "" Vector__XXX
 SG_ cmd : 0|8@1+ (1,0) [0|0] "" Vector__XXX

BO_ 2215233598 l4_testing_bl_cmd: 5 BITSTREAM
 SG_ data : 8|32@1+ (1,0) [0|0] "" Vector__XXX
 SG_ cmd : 0|8@1+ (1,0) [0|0] "" Vector__XXX

BO_ 2282342462 set_fault: 3 BITSTREAM
 SG_ value : 16|1@1+ (1,0) [0|0] "" Vector__XXX
 SG_ id : 0|16@1+ (1,0) [0|0] "" Vector__XXX

BO_ 2282342526 return_fault_control: 2 BITSTREAM
 SG_ id : 0|16@1+ (1,0) [0|0] "" Vector__XXX

BO_ 2566869221 elcon_charger_status: 5 Charger
 SG_ communication_fail : 36|1@1+ (1,0) [0|0] "" Vector__XXX
 SG_ startup_fail : 35|1@1+ (1,0) [0|0] "" Vector__XXX
 SG_ input_v_fail : 34|1@1+ (1,0) [0|0] "" Vector__XXX
 SG_ temp_fail : 33|1@1+ (1,0) [0|0] "" Vector__XXX
 SG_ hw_fail : 32|1@1+ (1,0) [0|0] "" Vector__XXX
 SG_ charge_current : 16|16@1+ (0.1,0) [0|0] "A" Vector__XXX
 SG_ charge_voltage : 0|16@1+ (0.1,0) [0|0] "V" Vector__XXX

BO_ 2483028082 daq_command_MAIN_MODULE: 8 DAQ
 SG_ daq_command : 0|64@1+ (1,0) [0|0] "" Vector__XXX

BO_ 2483028338 daq_command_DASHBOARD: 8 DAQ
 SG_ daq_command : 0|64@1+ (1,0) [0|0] "" Vector__XXX

BO_ 2483028274 daq_command_A_BOX: 8 DAQ
 SG_ daq_command : 0|64@1+ (1,0) [0|0] "" Vector__XXX

BO_ 2483028210 daq_command_DRIVELINE: 8 DAQ
 SG_ daq_command : 0|64@1+ (1,0) [0|0] "" Vector__XXX

BO_ 2483030002 daq_command_PDU: 8 DAQ
 SG_ daq_command : 0|64@1+ (1,0) [0|0] "" Vector__XXX

BO_ 2281733418 heat_req: 3 a_box
 SG_ time : 1|16@1+ (1,0) [0|0] "" Vector__XXX
 SG_ toggle : 0|1@1+ (1,0) [0|0] "" Vector__XXX

BO_ 2214624618 pack_curr: 2 a_box
 SG_ current : 0|16@1- (1,0) [0|0] "" Vector__XXX

BO_ 2348810282 balance_request: 2 a_box
 SG_ voltage_target : 0|16@1- (0.0001,0) [0|0] "" Vector__XXX

BO_ 2147486688 module_temp_0: 8 ARDUINO
 SG_ mod_temp_3 : 48|16@1+ (0.1,0) [0|0] "Cx10" Vector__XXX
 SG_ mod_temp_2 : 32|16@1+ (0.1,0) [0|0] "Cx10" Vector__XXX
 SG_ mod_temp_1 : 16|16@1+ (0.1,0) [0|0] "Cx10" Vector__XXX
 SG_ mod_temp_0 : 0|16@1+ (0.1,0) [0|0] "Cx10" Vector__XXX

BO_ 2147486689 module_temp_1: 8 ARDUINO
 SG_ mod_temp_3 : 48|16@1+ (0.1,0) [0|0] "Cx10" Vector__XXX
 SG_ mod_temp_2 : 32|16@1+ (0.1,0) [0|0] "Cx10" Vector__XXX
 SG_ mod_temp_1 : 16|16@1+ (0.1,0) [0|0] "Cx10" Vector__XXX
 SG_ mod_temp_0 : 0|16@1+ (0.1,0) [0|0] "Cx10" Vector__XXX

BO_ 2147486690 module_temp_2: 8 ARDUINO
 SG_ mod_temp_3 : 48|16@1+ (0.1,0) [0|0] "Cx10" Vector__XXX
 SG_ mod_temp_2 : 32|16@1+ (0.1,0) [0|0] "Cx10" Vector__XXX
 SG_ mod_temp_1 : 16|16@1+ (0.1,0) [0|0] "Cx10" Vector__XXX
 SG_ mod_temp_0 : 0|16@1+ (0.1,0) [0|0] "Cx10" Vector__XXX

BO_ 2147486691 module_temp_3: 8 ARDUINO
 SG_ mod_temp_3 : 48|16@1+ (0.1,0) [0|0] "Cx10" Vector__XXX
 SG_ mod_temp_2 : 32|16@1+ (0.1,0) [0|0] "Cx10" Vector__XXX
 SG_ mod_temp_1 : 16|16@1+ (0.1,0) [0|0] "Cx10" Vector__XXX
 SG_ mod_temp_0 : 0|16@1+ (0.1,0) [0|0] "Cx10" Vector__XXX

BO_ 2147486692 module_temp_4: 8 ARDUINO
 SG_ mod_temp_3 : 48|16@1+ (0.1,0) [0|0] "Cx10" Vector__XXX
 SG_ mod_temp_2 : 32|16@1+ (0.1,0) [0|0] "Cx10" Vector__XXX
 SG_ mod_temp_1 : 16|16@1+ (0.1,0) [0|0] "Cx10" Vector__XXX
 SG_ mod_temp_0 : 0|16@1+ (0.1,0) [0|0] "Cx10" Vector__XXX

BO_ 2147486693 module_temp_5: 8 ARDUINO
 SG_ mod_temp_3 : 48|16@1+ (0.1,0) [0|0] "Cx10" Vector__XXX
 SG_ mod_temp_2 : 32|16@1+ (0.1,0) [0|0] "Cx10" Vector__XXX
 SG_ mod_temp_1 : 16|16@1+ (0.1,0) [0|0] "Cx10" Vector__XXX
 SG_ mod_temp_0 : 0|16@1+ (0.1,0) [0|0] "Cx10" Vector__XXX

BO_ 2147486694 module_temp_6: 8 ARDUINO
 SG_ mod_temp_3 : 48|16@1+ (0.1,0) [0|0] "Cx10" Vector__XXX
 SG_ mod_temp_2 : 32|16@1+ (0.1,0) [0|0] "Cx10" Vector__XXX
 SG_ mod_temp_1 : 16|16@1+ (0.1,0) [0|0] "Cx10" Vector__XXX
 SG_ mod_temp_0 : 0|16@1+ (0.1,0) [0|0] "Cx10" Vector__XXX

BO_ 2147486695 module_temp_7: 8 ARDUINO
 SG_ mod_temp_3 : 48|16@1+ (0.1,0) [0|0] "Cx10" Vector__XXX
 SG_ mod_temp_2 : 32|16@1+ (0.1,0) [0|0] "Cx10" Vector__XXX
 SG_ mod_temp_1 : 16|16@1+ (0.1,0) [0|0] "Cx10" Vector__XXX
 SG_ mod_temp_0 : 0|16@1+ (0.1,0) [0|0] "Cx10" Vector__XXX

BO_ 2147486696 module_temp_8: 8 ARDUINO
 SG_ mod_temp_3 : 48|16@1+ (0.1,0) [0|0] "Cx10" Vector__XXX
 SG_ mod_temp_2 : 32|16@1+ (0.1,0) [0|0] "Cx10" Vector__XXX
 SG_ mod_temp_1 : 16|16@1+ (0.1,0) [0|0] "Cx10" Vector__XXX
 SG_ mod_temp_0 : 0|16@1+ (0.1,0) [0|0] "Cx10" Vector__XXX

BO_ 2147486697 module_temp_9: 8 ARDUINO
 SG_ mod_temp_3 : 48|16@1+ (0.1,0) [0|0] "Cx10" Vector__XXX
 SG_ mod_temp_2 : 32|16@1+ (0.1,0) [0|0] "Cx10" Vector__XXX
 SG_ mod_temp_1 : 16|16@1+ (0.1,0) [0|0] "Cx10" Vector__XXX
 SG_ mod_temp_0 : 0|16@1+ (0.1,0) [0|0] "Cx10" Vector__XXX

BO_ 2147486698 module_temp_10: 8 ARDUINO
 SG_ mod_temp_3 : 48|16@1+ (0.1,0) [0|0] "Cx10" Vector__XXX
 SG_ mod_temp_2 : 32|16@1+ (0.1,0) [0|0] "Cx10" Vector__XXX
 SG_ mod_temp_1 : 16|16@1+ (0.1,0) [0|0] "Cx10" Vector__XXX
 SG_ mod_temp_0 : 0|16@1+ (0.1,0) [0|0] "Cx10" Vector__XXX

BO_ 2147486699 module_temp_11: 8 ARDUINO
 SG_ mod_temp_3 : 48|16@1+ (0.1,0) [0|0] "Cx10" Vector__XXX
 SG_ mod_temp_2 : 32|16@1+ (0.1,0) [0|0] "Cx10" Vector__XXX
 SG_ mod_temp_1 : 16|16@1+ (0.1,0) [0|0] "Cx10" Vector__XXX
 SG_ mod_temp_0 : 0|16@1+ (0.1,0) [0|0] "Cx10" Vector__XXX

BO_ 2147486700 module_temp_12: 8 ARDUINO
 SG_ mod_temp_3 : 48|16@1+ (0.1,0) [0|0] "Cx10" Vector__XXX
 SG_ mod_temp_2 : 32|16@1+ (0.1,0) [0|0] "Cx10" Vector__XXX
 SG_ mod_temp_1 : 16|16@1+ (0.1,0) [0|0] "Cx10" Vector__XXX
 SG_ mod_temp_0 : 0|16@1+ (0.1,0) [0|0] "Cx10" Vector__XXX

BO_ 2147486701 module_temp_13: 8 ARDUINO
 SG_ mod_temp_3 : 48|16@1+ (0.1,0) [0|0] "Cx10" Vector__XXX
 SG_ mod_temp_2 : 32|16@1+ (0.1,0) [0|0] "Cx10" Vector__XXX
 SG_ mod_temp_1 : 16|16@1+ (0.1,0) [0|0] "Cx10" Vector__XXX
 SG_ mod_temp_0 : 0|16@1+ (0.1,0) [0|0] "Cx10" Vector__XXX

BO_ 2147486702 module_temp_14: 8 ARDUINO
 SG_ mod_temp_3 : 48|16@1+ (0.1,0) [0|0] "Cx10" Vector__XXX
 SG_ mod_temp_2 : 32|16@1+ (0.1,0) [0|0] "Cx10" Vector__XXX
 SG_ mod_temp_1 : 16|16@1+ (0.1,0) [0|0] "Cx10" Vector__XXX
 SG_ mod_temp_0 : 0|16@1+ (0.1,0) [0|0] "Cx10" Vector__XXX

BO_ 2147486703 module_temp_15: 8 ARDUINO
 SG_ mod_temp_3 : 48|16@1+ (0.1,0) [0|0] "Cx10" Vector__XXX
 SG_ mod_temp_2 : 32|16@1+ (0.1,0) [0|0] "Cx10" Vector__XXX
 SG_ mod_temp_1 : 16|16@1+ (0.1,0) [0|0] "Cx10" Vector__XXX
 SG_ mod_temp_0 : 0|16@1+ (0.1,0) [0|0] "Cx10" Vector__XXX

BO_ 2483029759 orion_currents_volts2: 4 TEST_NODE
 SG_ pack_voltage : 16|16@1+ (0.1,0) [0|0] "V" Vector__XXX
 SG_ pack_current : 0|16@1- (0.1,0) [0|0] "A" Vector__XXX

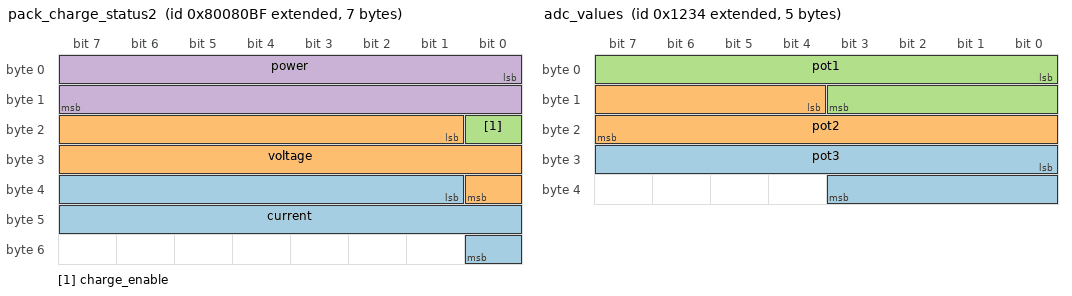
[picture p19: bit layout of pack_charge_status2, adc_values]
BO_ 2281734335 pack_charge_status2: 7 TEST_NODE
 SG_ current : 33|16@1+ (0.1,0) [0|0] "A" Vector__XXX
 SG_ voltage : 17|16@1+ (0.1,0) [0|0] "V" Vector__XXX
 SG_ charge_enable : 16|1@1+ (1,0) [0|0] "" Vector__XXX
 SG_ power : 0|16@1+ (1,0) [0|0] "W" Vector__XXX

BO_ 2483028095 test_msg: 2 TEST_NODE
 SG_ test_sig : 0|16@1- (1,0) [0|0] "" Vector__XXX

BO_ 2483028159 test_msg2: 2 TEST_NODE
 SG_ test_sig2 : 0|16@1+ (1,0) [0|0] "" Vector__XXX

BO_ 2483028223 test_msg3: 2 TEST_NODE
 SG_ test_sig3 : 0|16@1+ (1,0) [0|0] "" Vector__XXX

BO_ 2483028287 test_msg4: 2 TEST_NODE
 SG_ test_sig4 : 0|16@1+ (1,0) [0|0] "" Vector__XXX

BO_ 2483028351 test_msg5: 2 TEST_NODE
 SG_ test_sig5 : 0|16@1+ (1,0) [0|0] "" Vector__XXX

BO_ 2348810751 wheel_speeds: 8 TEST_NODE
 SG_ right_speed : 32|32@1- (1,0) [0|0] "kph" Vector__XXX
 SG_ left_speed : 0|32@1- (1,0) [0|0] "kph" Vector__XXX

BO_ 2147488308 adc_values: 5 TEST_NODE
 SG_ pot3 : 24|12@1+ (1,0) [0|0] "" Vector__XXX
 SG_ pot2 : 12|12@1+ (1,0) [0|0] "" Vector__XXX
 SG_ pot1 : 0|12@1+ (1,0) [0|0] "" Vector__XXX

BO_ 2347693088 car_state: 1 TEST_NODE
 SG_ car_state : 0|8@1+ (1,0) [0|0] "" Vector__XXX

BO_ 2148060095 fault_sync_test_node: 3 TEST_NODE
 SG_ latched : 16|1@1+ (1,0) [0|0] "" Vector__XXX
 SG_ idx : 0|16@1+ (1,0) [0|0] "" Vector__XXX

BO_ 2550136831 daq_response_TEST_NODE: 8 TEST_NODE
 SG_ daq_response : 0|64@1+ (1,0) [0|0] "" Vector__XXX

BO_ 2483028093 test_msg_2: 2 TEST_NODE_2
 SG_ test_sig : 0|16@1+ (1,0) [0|0] "" Vector__XXX

BO_ 2483028157 test_msg2_2: 2 TEST_NODE_2
 SG_ test_sig2 : 0|16@1+ (1,0) [0|0] "" Vector__XXX

BO_ 2483028221 test_msg3_2: 2 TEST_NODE_2
 SG_ test_sig3 : 0|16@1+ (1,0) [0|0] "" Vector__XXX

BO_ 2483028285 test_msg4_2: 2 TEST_NODE_2
 SG_ test_sig4 : 0|16@1+ (1,0) [0|0] "" Vector__XXX

BO_ 2483028349 test_msg5_2: 8 TEST_NODE_2
 SG_ test_sig5_3 : 32|32@1- (1,0) [0|0] "" Vector__XXX
 SG_ test_sig5_2 : 16|16@1- (1,0) [0|0] "" Vector__XXX
 SG_ test_sig5 : 0|16@1+ (1,0) [0|0] "" Vector__XXX

BO_ 2147492386 test_stale: 1 TEST_NODE_2
 SG_ data : 0|8@1+ (1,0) [0|0] "" Vector__XXX

BO_ 2347693089 car_state2: 1 TEST_NODE_2
 SG_ car_state2 : 0|8@1+ (1,0) [0|0] "" Vector__XXX

BO_ 2483032050 daq_command_TEST_NODE: 8 DAQ
 SG_ daq_command : 0|64@1+ (1,0) [0|0] "" Vector__XXX

CM_ BO_ 2214598913 "Heart beat message for main module";
CM_ SG_ 2214598913 car_state "Main car state";
CM_ BO_ 2214592577 "Torque request for all motors, temporarily from main.";
CM_ SG_ 2214592577 rear_right "torque request. -4095-4095";
CM_ SG_ 2214592577 rear_left "torque request. -4095-4095";
CM_ SG_ 2214592577 front_right "torque request. -4095-4095";
CM_ SG_ 2214592577 front_left "torque request. -4095-4095";
CM_ BO_ 2214594689 "Flowrate and Water temp of cooling loops";
CM_ SG_ 2214594689 drivetrain_fan_speed "Speed of drivetrain fan";
CM_ SG_ 2214594689 battery_fan_speed "Speed of battery fan";
CM_ SG_ 2214594689 drivetrain_flowrate "Flow rate for drivetrain coolant loop";
CM_ SG_ 2214594689 battery_flowrate "Flow rate for battery coolant loop";
CM_ SG_ 2214594689 drivetrain_out_temp "Out flow temperature of drivetrain coolant loop";
CM_ SG_ 2214594689 drivetrain_in_temp "In flow temperature of drivetrain coolant loop";
CM_ SG_ 2214594689 battery_out_temp "Out flow temperature of battery coolant loop";
CM_ SG_ 2214594689 battery_in_temp "In flow temperature of battery coolant loop";
CM_ BO_ 2214594753 "outputs to coolant loops";
CM_ BO_ 2415921409 "Gearbox temps";
CM_ BO_ 1984 "Steering sensor configuration";
CM_ BO_ 2415925505 "Local main LV voltage rail measurements";
CM_ BO_ 2281707649 "precharge validation update";
CM_ SG_ 2281707649 precharge_error "Precharge error found";
CM_ SG_ 2281707649 precharge_complete "Precharge complete state";
CM_ SG_ 2281707649 v_bat "Battery Voltage";
CM_ SG_ 2281707649 v_mc "Motor Controller Voltage";
CM_ BO_ 2415925569 "Local main LV current measurements and additional info";
CM_ SG_ 2415925569 LV3V3_PG "Power good status pin on the 3V3 LDO";
CM_ BO_ 2415925633 "performance metrics of MCU";
CM_ SG_ 2415925633 can_tx_fails "Number of CAN transmit failures";
CM_ SG_ 2415925633 sched_error "PSCHED Error Flags (bit #)
 0 - N/A
1 - no free task
2 - FG Miss
3 - BG Miss
4 - Individual FG Miss";
CM_ SG_ 2415925633 background_use "Percent of the 1ms loop time used by background tasks";
CM_ SG_ 2415925633 foreground_use "Percent of the 1ms loop time used by foreground tasks";
CM_ SG_ 2415925633 sched_skips "Number of loop misses (execution time was skipped)";
CM_ BO_ 2214598977 "rear drivline heart beat";
CM_ BO_ 2348810945 "DC Current and Temperature of the motors";
CM_ BO_ 2348811137 "Shutdown Circuit Status";
CM_ BO_ 2348811009 "Temperature of motor controllers";
CM_ BO_ 2281702273 "Rear Wheel speeds from motor controllers";
CM_ BO_ 2148059649 "Fault status message";
CM_ BO_ 2550136769 "daq response from node MAIN_MODULE";
CM_ BO_ 2214592578 "Torque request for all motors.";
CM_ SG_ 2214592578 rear_right "torque request. 0-4096";
CM_ SG_ 2214592578 rear_left "torque request. 0-4096";
CM_ SG_ 2214592578 front_right "torque request. 0-4096";
CM_ SG_ 2214592578 front_left "torque request. 0-4096";
CM_ BO_ 2147490050 "Status message for bitstream flashing";
CM_ SG_ 2147490050 flash_timeout_rx "Timeout from CAN rx";
CM_ SG_ 2147490050 flash_success "Done flashing bitstream";
CM_ BO_ 2148059714 "Fault status message";
CM_ BO_ 2214598915 "front drivline heart beat";
CM_ BO_ 2214592515 "Wheel data for the rear tires";
CM_ SG_ 2214592515 right_normal "Linear potentiometer distance between mounting points";
CM_ SG_ 2214592515 left_normal "Linear potentiometer distance between mounting points";
CM_ BO_ 2214592579 "Wheel data for the rear tires";
CM_ SG_ 2214592579 right_normal "Linear potentiometer distance between mounting points";
CM_ SG_ 2214592579 left_normal "Linear potentiometer distance between mounting points";
CM_ BO_ 2214593667 "Rear request to motor controllers";
CM_ BO_ 2214593731 "Rear request to motor controllers";
CM_ BO_ 2348810883 "DC Current and Temperature of the motors";
CM_ BO_ 2148059779 "Fault status message";
CM_ BO_ 2550136771 "daq response from node DRIVELINE";
CM_ BO_ 2214598980 "heart beat for precharge";
CM_ BO_ 2550588916 "Charge voltage and current request to ELCON charger";
CM_ SG_ 2550588916 charge_disable "Disable charging";
CM_ SG_ 2550588916 current_limit "Charge current";
CM_ SG_ 2550588916 voltage_limit "Charge voltage";
CM_ BO_ 2281734340 "Number of wonky thermistors on pack";
CM_ SG_ 2281734340 module_4 "Number of thermistors > 1.5v";
CM_ SG_ 2281734340 module_3 "Number of thermistors > 1.5v";
CM_ SG_ 2281734340 module_2 "Number of thermistors > 1.5v";
CM_ SG_ 2281734340 module_1 "Number of thermistors > 1.5v";
CM_ BO_ 2281734276 "Send charge information";
CM_ SG_ 2281734276 current "Instantaneous charge current";
CM_ SG_ 2281734276 voltage "Instantaneous charge voltage";
CM_ SG_ 2281734276 charge_enable "Charge mode enable";
CM_ SG_ 2281734276 power "Instantaneous charge power";
CM_ BO_ 2214625284 "Angular rate data";
CM_ BO_ 2214625348 "Acceleration rate data";
CM_ BO_ 2214625540 "Angle data from bsxlite software";
CM_ BO_ 2214913540 "maximum cell temperature for the whole pack";
CM_ BO_ 2483060868 "Average cell temperature for each module";
CM_ BO_ 2483060996 "Max cell temperature for each module";
CM_ BO_ 2483061252 "Min cell temperature for each module";
CM_ BO_ 2483060932 "Raw cell temperature for each module of thermistor at index";
CM_ BO_ 2148059844 "Fault status message";
CM_ BO_ 2550136772 "daq response from node A_BOX";
CM_ BO_ 2483029688 "charge, State, Current/voltage limits";
CM_ BO_ 2483029752 "Pack current + voltage";
CM_ BO_ 2348812088 "Pack DTC Flags";
CM_ BO_ 2348810935 "gps velocity";
CM_ BO_ 2348819255 "gps position";
CM_ BO_ 2348819319 "gps coordinates";
CM_ BO_ 2348810999 "gyroscope from imu";
CM_ BO_ 2348819383 "acceleration from imu";
CM_ BO_ 2348819447 "magnetic from bmm";
CM_ BO_ 2348902711 "position from sfs";
CM_ BO_ 2348902775 "velocity from sfs";
CM_ BO_ 2348902839 "acceleratoin from sfs";
CM_ BO_ 2348902903 "orientation from sfs";
CM_ BO_ 2348902967 "orientation vel from sfs";
CM_ BO_ 2348819895 "throttle remapped";
CM_ BO_ 2483028613 "Throttle and brake values";
CM_ BO_ 2348810949 "Cooling Pump/Fan requests from Dash LCD";
CM_ BO_ 2214593093 "Filtered throttle and brake values";
CM_ BO_ 2214592517 "Car start button pressed";
CM_ BO_ 2214598917 "periodic dashboard heartbeat";
CM_ BO_ 2214598981 "periodic dashboard MCU temp";
CM_ BO_ 2148059909 "Fault status message";
CM_ BO_ 2550136773 "daq response from node DASHBOARD";
CM_ BO_ 688 "Standard steering angle and speed";
CM_ BO_ 2214659103 "periodic dashboard heartbeat";
CM_ BO_ 2148059999 "Fault status message";
CM_ BO_ 2550136799 "daq response from node PDU";
CM_ BO_ 372 "Y Acceleration Update";
CM_ BO_ 376 "X Acceleration Update";
CM_ BO_ 380 "Z Acceleration Update";
CM_ BO_ 2214912572 "Main Module Bootloader response";
CM_ BO_ 2214912636 "Dashboard Bootloader response";
CM_ BO_ 2214912700 "Torque Vector Bootloader response";
CM_ BO_ 2214912764 "Torque Vector Bootloader response";
CM_ BO_ 2214912828 "Torque Vector Bootloader response";
CM_ BO_ 2214912892 "Torque Vector Bootloader response";
CM_ BO_ 2214912956 "Torque Vector Bootloader response";
CM_ BO_ 2214913020 "Torque Vector Bootloader response";
CM_ BO_ 2214913084 "Torque Vector Bootloader response";
CM_ BO_ 2214913148 "Torque Vector Bootloader response";
CM_ BO_ 2214913212 "Torque Vector Bootloader response";
CM_ BO_ 2214913276 "Torque Vector Bootloader response";
CM_ BO_ 2214913340 "Torque Vector Bootloader response";
CM_ BO_ 2214913404 "Torque Vector Bootloader response";
CM_ BO_ 2214913468 "Torque Vector Bootloader response";
CM_ BO_ 2214913532 "Torque Vector Bootloader response";
CM_ BO_ 2214913596 "L4 Test Bootloader response";
CM_ BO_ 2281733446 "Estimated soc";
CM_ SG_ 2281733446 soc3 "Cell 2 in % * 100";
CM_ SG_ 2281733446 soc2 "Cell 1 in % * 100";
CM_ SG_ 2281733446 soc1 "Cell 0 in % * 100";
CM_ SG_ 2281733446 idx "Index of each set";
CM_ BO_ 2214624646 "Measured cell voltages";
CM_ SG_ 2214624646 v3 "Cell 2 in V * 10000";
CM_ SG_ 2214624646 v2 "Cell 1 in V * 10000";
CM_ SG_ 2214624646 v1 "Cell 0 in V * 10000";
CM_ SG_ 2214624646 idx "Index of each set";
CM_ BO_ 2281733574 "Pack information";
CM_ SG_ 2281733574 bal_flags "Balance flags. 1 for on";
CM_ SG_ 2281733574 error "Error flags (non-zero is fault)";
CM_ SG_ 2281733574 volts "Pack voltage in V * 10000";
CM_ BO_ 2214624774 "Measured cell temperatures";
CM_ SG_ 2214624774 t3 "Cell 2 in deg C * 10000";
CM_ SG_ 2214624774 t2 "Cell 1 in deg C * 10000";
CM_ SG_ 2214624774 t1 "Cell 0 in deg C * 10000";
CM_ SG_ 2214624774 idx "Index of each set";
CM_ BO_ 2281733702 "Cell information";
CM_ SG_ 2281733702 uv "Under-voltage flags. 1 for fault";
CM_ SG_ 2281733702 ov "Over-voltage flags. 1 for fault";
CM_ SG_ 2281733702 delta "Max cell delta in V * 10000";
CM_ BO_ 2214624902 "Power limits";
CM_ SG_ 2214624902 chg_lim "Charge limit in W";
CM_ SG_ 2214624902 disch_lim "Discharge limit in W";
CM_ BO_ 2214598974 "Bitstream download command";
CM_ SG_ 2214598974 d7 "Bitstream data word 7";
CM_ SG_ 2214598974 d6 "Bitstream data word 6";
CM_ SG_ 2214598974 d5 "Bitstream data word 5";
CM_ SG_ 2214598974 d4 "Bitstream data word 4";
CM_ SG_ 2214598974 d3 "Bitstream data word 3";
CM_ SG_ 2214598974 d2 "Bitstream data word 2";
CM_ SG_ 2214598974 d1 "Bitstream data word 1";
CM_ SG_ 2214598974 d0 "Bitstream data word 0";
CM_ BO_ 2415925630 "Bitstream state command";
CM_ SG_ 2415925630 download_size "size for expected bitstream download (bytes)";
CM_ SG_ 2415925630 download_request "Request to download new bitstream";
CM_ BO_ 2215232574 "Bootloader command for main module";
CM_ SG_ 2215232574 data "Bootloader data";
CM_ SG_ 2215232574 cmd "Bootloader Command type";
CM_ BO_ 2215232638 "Bootloader command for dashboard";
CM_ SG_ 2215232638 data "Bootloader data";
CM_ SG_ 2215232638 cmd "Bootloader Command type";
CM_ BO_ 2215232702 "Bootloader command for torque vector";
CM_ SG_ 2215232702 data "Bootloader data";
CM_ SG_ 2215232702 cmd "Bootloader Command type";
CM_ BO_ 2215232766 "Bootloader command for torque vector";
CM_ SG_ 2215232766 data "Bootloader data";
CM_ SG_ 2215232766 cmd "Bootloader Command type";
CM_ BO_ 2215232830 "Bootloader command for torque vector";
CM_ SG_ 2215232830 data "Bootloader data";
CM_ SG_ 2215232830 cmd "Bootloader Command type";
CM_ BO_ 2215232894 "Bootloader command for torque vector";
CM_ SG_ 2215232894 data "Bootloader data";
CM_ SG_ 2215232894 cmd "Bootloader Command type";
CM_ BO_ 2215232958 "Bootloader command for torque vector";
CM_ SG_ 2215232958 data "Bootloader data";
CM_ SG_ 2215232958 cmd "Bootloader Command type";
CM_ BO_ 2215233022 "Bootloader command for torque vector";
CM_ SG_ 2215233022 data "Bootloader data";
CM_ SG_ 2215233022 cmd "Bootloader Command type";
CM_ BO_ 2215233086 "Bootloader command for torque vector";
CM_ SG_ 2215233086 data "Bootloader data";
CM_ SG_ 2215233086 cmd "Bootloader Command type";
CM_ BO_ 2215233150 "Bootloader command for torque vector";
CM_ SG_ 2215233150 data "Bootloader data";
CM_ SG_ 2215233150 cmd "Bootloader Command type";
CM_ BO_ 2215233214 "Bootloader command for torque vector";
CM_ SG_ 2215233214 data "Bootloader data";
CM_ SG_ 2215233214 cmd "Bootloader Command type";
CM_ BO_ 2215233278 "Bootloader command for torque vector";
CM_ SG_ 2215233278 data "Bootloader data";
CM_ SG_ 2215233278 cmd "Bootloader Command type";
CM_ BO_ 2215233342 "Bootloader command for torque vector";
CM_ SG_ 2215233342 data "Bootloader data";
CM_ SG_ 2215233342 cmd "Bootloader Command type";
CM_ BO_ 2215233406 "Bootloader command for torque vector";
CM_ SG_ 2215233406 data "Bootloader data";
CM_ SG_ 2215233406 cmd "Bootloader Command type";
CM_ BO_ 2215233470 "Bootloader command for torque vector";
CM_ SG_ 2215233470 data "Bootloader data";
CM_ SG_ 2215233470 cmd "Bootloader Command type";
CM_ BO_ 2215233534 "Bootloader command for torque vector";
CM_ SG_ 2215233534 data "Bootloader data";
CM_ SG_ 2215233534 cmd "Bootloader Command type";
CM_ BO_ 2215233598 "Bootloader command for l4 testing";
CM_ SG_ 2215233598 data "Bootloader data";
CM_ SG_ 2215233598 cmd "Bootloader Command type";
CM_ BO_ 2282342462 "Set a fault";
CM_ SG_ 2282342462 value "Bootloader data";
CM_ SG_ 2282342462 id "Bootloader Command type";
CM_ BO_ 2282342526 "Return control of fault back to the MCU";
CM_ SG_ 2282342526 id "Fault ID";
CM_ BO_ 2566869221 "Realtime charger status";
CM_ SG_ 2566869221 communication_fail " 5s timeout from communication failure";
CM_ SG_ 2566869221 startup_fail "Startup voltage detection failure";
CM_ SG_ 2566869221 input_v_fail "Input voltage failure";
CM_ SG_ 2566869221 temp_fail "Temperature failure";
CM_ SG_ 2566869221 hw_fail "Hardware failure";
CM_ BO_ 2483028082 "daq command for node MAIN_MODULE";
CM_ BO_ 2483028338 "daq command for node DASHBOARD";
CM_ BO_ 2483028274 "daq command for node A_BOX";
CM_ BO_ 2483028210 "daq command for node DRIVELINE";
CM_ BO_ 2483030002 "daq command for node PDU";
CM_ BO_ 2281733418 "Starts BMS pre-heat for set time";
CM_ SG_ 2281733418 time "Set runtime in ms";
CM_ SG_ 2281733418 toggle "1 for start, 0 for stop";
CM_ BO_ 2214624618 "Pack current";
CM_ SG_ 2214624618 current "Pack current";
CM_ BO_ 2348810282 "Global cell balance request setpoint";
CM_ SG_ 2348810282 voltage_target "Global balance target";
CM_ BO_ 2147486688 "Cell temps from each module";
CM_ BO_ 2147486689 "Cell temps from each module";
CM_ BO_ 2147486690 "Cell temps from each module";
CM_ BO_ 2147486691 "Cell temps from each module";
CM_ BO_ 2147486692 "Cell temps from each module";
CM_ BO_ 2147486693 "Cell temps from each module";
CM_ BO_ 2147486694 "Cell temps from each module";
CM_ BO_ 2147486695 "Cell temps from each module";
CM_ BO_ 2147486696 "Cell temps from each module";
CM_ BO_ 2147486697 "Cell temps from each module";
CM_ BO_ 2147486698 "Cell temps from each module";
CM_ BO_ 2147486699 "Cell temps from each module";
CM_ BO_ 2147486700 "Cell temps from each module";
CM_ BO_ 2147486701 "Cell temps from each module";
CM_ BO_ 2147486702 "Cell temps from each module";
CM_ BO_ 2147486703 "Cell temps from each module";
CM_ BO_ 2483029759 "Pack current + voltage";
CM_ BO_ 2281734335 "Send charge information";
CM_ SG_ 2281734335 current "Instantaneous charge current";
CM_ SG_ 2281734335 voltage "Instantaneous charge voltage";
CM_ SG_ 2281734335 charge_enable "Charge mode enable";
CM_ SG_ 2281734335 power "Instantaneous charge power";
CM_ BO_ 2483028095 "test_msg desc";
CM_ BO_ 2483028159 "test_msg2 desc";
CM_ BO_ 2483028223 "test_msg2 desc";
CM_ BO_ 2483028287 "test_msg4 desc";
CM_ BO_ 2483028351 "test_msg5 desc";
CM_ BO_ 2348810751 "wheel speeds";
CM_ BO_ 2147488308 "adc potentiometer readings";
CM_ BO_ 2347693088 "state of the car";
CM_ BO_ 2148060095 "Fault status message";
CM_ BO_ 2550136831 "daq response from node TEST_NODE";
CM_ BO_ 2483028093 "test_msg desc";
CM_ BO_ 2483028157 "test_msg2 desc";
CM_ BO_ 2483028221 "test_msg2 desc";
CM_ BO_ 2483028285 "test_msg4 desc";
CM_ BO_ 2483028349 "test_msg5 desc";
CM_ BO_ 2147492386 "used to test stale";
CM_ BO_ 2347693089 "state of the car";
CM_ BO_ 2483032050 "daq command for node TEST_NODE";

VAL_ 2214598913 car_state 0 "idle" 1 "buzzing" 2 "ready2drive" 3 "error" 4 "fatal" 5 "reset" 6 "recover" 7 "fan_ctrl" ;
VAL_ 2214598977 rear_right_last_link_error 0 "none" 1 "not_serial" 2 "cmd_timeout" 3 "gen_timeout" ;
VAL_ 2214598977 rear_right_motor_link 0 "disconnected" 1 "attempting" 2 "verifying" 3 "delay" 4 "connected" 5 "fail" ;
VAL_ 2214598977 rear_right_motor 0 "disconnected" 1 "connected" 2 "config" 3 "error" ;
VAL_ 2214598977 rear_left_last_link_error 0 "none" 1 "not_serial" 2 "cmd_timeout" 3 "gen_timeout" ;
VAL_ 2214598977 rear_left_motor_link 0 "disconnected" 1 "attempting" 2 "verifying" 3 "delay" 4 "connected" 5 "fail" ;
VAL_ 2214598977 rear_left_motor 0 "disconnected" 1 "connected" 2 "config" 3 "error" ;
VAL_ 2214598915 front_right_last_link_error 0 "none" 1 "not_serial" 2 "cmd_timeout" 3 "gen_timeout" ;
VAL_ 2214598915 front_right_motor_link 0 "disconnected" 1 "attempting" 2 "verifying" 3 "delay" 4 "connected" 5 "fail" ;
VAL_ 2214598915 front_right_motor 0 "disconnected" 1 "connected" 2 "config" 3 "error" ;
VAL_ 2214598915 front_left_last_link_error 0 "none" 1 "not_serial" 2 "cmd_timeout" 3 "gen_timeout" ;
VAL_ 2214598915 front_left_motor_link 0 "disconnected" 1 "attempting" 2 "verifying" 3 "delay" 4 "connected" 5 "fail" ;
VAL_ 2214598915 front_left_motor 0 "disconnected" 1 "connected" 2 "config" 3 "error" ;
VAL_ 2347693088 car_state 0 "ready2go" 1 "flipped" 2 "flying" 3 "lightspeed" ;
VAL_ 2347693089 car_state2 0 "ready2go" 1 "flipped" 2 "flying" 3 "lightspeed" ;
SIG_VALTYPE_ 2214593667 left_cmd : 1;
SIG_VALTYPE_ 2214593667 right_cmd : 1;
SIG_VALTYPE_ 2214593731 T : 1;
SIG_VALTYPE_ 2214593731 P_c : 1;
SIG_VALTYPE_ 2348810751 left_speed : 1;
SIG_VALTYPE_ 2348810751 right_speed : 1;
SIG_VALTYPE_ 2483028349 test_sig5_3 : 1;
